[part 13 of 23: package /Cluster]
AUTOSAR XML (schema 4-3-0)
package /Cluster  (continued)
  7 x lin cluster, all with baudrate=19200, protocol-name=LIN, protocol-version=2.0:  (continued)
    Klima_LIN7
      lin physical channel CHNL: comm-connectors=CN_Klima_LIN7
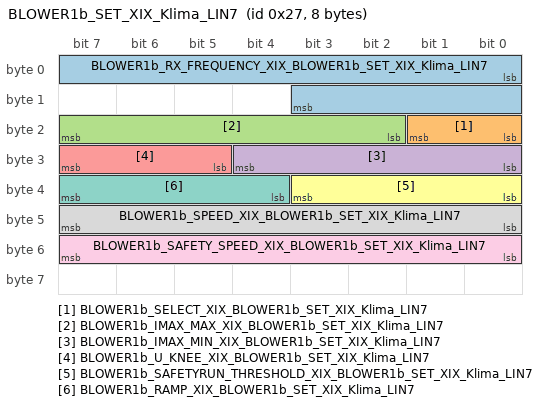
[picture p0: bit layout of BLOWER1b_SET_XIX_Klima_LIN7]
        frame BLOWER1b_SET_XIX_Klima_LIN7: id 0x27, from Klima, frame-length=8, lin-checksum=ENHANCED
          pdu BLOWER1b_SET_XIX_Klima_LIN7: length=8, unused-bit-pattern=0
            signal BLOWER1b_RX_FREQUENCY_XIX_BLOWER1b_SET_XIX_Klima_LIN7: start 0, 12 bit, little-endian, data-type-policy=OVERRIDE, i-signal-type=PRIMITIVE, base-type=BT_BLOWER1b_RX_FREQUENCY, compu {phys=raw+150 for raw 0..1896, 4095=Cxfff_ungueltig (CM_BLOWER1b_RX_FREQUENCY_Cxfff_ungueltig); unit Unit_KiloHertz}, range phys 150..2046 Unit_KiloHertz, raw 0..4095, unit=Unit_KiloHertz, transfer-property=PENDING  # Radio-Empfangsfrequenz bei AM-Empfang 0..1896: Radio RX-Frequenz in kHz 150 kHz.. 2046 kHz (Offset 150 kHz) diese Frequenz Störungsfrei halten. 1897 .. 4094 rerserviert, Ersatzwert: oberste einstellbare Frequenz 4095: ungueltig, Ersatzwert: oberste einstellbare Frequenz
            signal BLOWER1b_SELECT_XIX_BLOWER1b_SET_XIX_Klima_LIN7: start 16, 2 bit, little-endian, data-type-policy=OVERRIDE, i-signal-type=PRIMITIVE, init-value=0, base-type=BT_BLOWER1b_SELECT, compu {0=Cx0_BLOWER1 (CM_BLOWER1b_SELECT_Cx0_BLOWER1), 1=Cx1_BLOWER3 (CM_BLOWER1b_SELECT_Cx1_BLOWER3), 2=Cx2_reserviert (CM_BLOWER1b_SELECT_Cx2_reserviert), 3=Cx3_ungueltig (CM_BLOWER1b_SELECT_Cx3_ungueltig)}, range raw 0..3, transfer-property=PENDING  # 00 : Blower 1 wenn / when ID-field = 0x27 Blower 2 wenn / when ID-field = 0x3A 01 : Blower 3 wenn / when ID-field = 0x27 Blower 4 wenn/ when ID-field = 0x3A 10 : reserviert, Ersatzwert: Blower 2 11 : ungültig, Ersatzwert: Blower 2
            signal BLOWER1b_IMAX_MAX_XIX_BLOWER1b_SET_XIX_Klima_LIN7: start 18, 6 bit, little-endian, data-type-policy=OVERRIDE, i-signal-type=PRIMITIVE, init-value=0, base-type=BT_BLOWER1b_IMAX_MAX, compu {phys=raw*0.5+8 for raw 0..62, 63=Cx3f_ungueltig (CM_BLOWER1b_IMAX_MAX_Cx3f_ungueltig); unit Unit_Amper}, range phys 8..39 Unit_Amper, raw 0..63, unit=Unit_Amper, transfer-property=PENDING  # Vorgabe Maximalstrombegrenzung bei hoher Motorspannung 0.. 62 : Maximalstrom 8 A .. 39 A, Auflösung 0,5 A*inc + 8A. 63 : ungueltig Ersatzwert: niedrigster einstellbarer Wert Regler begrenzt auf Maximalwert
            signal BLOWER1b_IMAX_MIN_XIX_BLOWER1b_SET_XIX_Klima_LIN7: start 24, 5 bit, little-endian, data-type-policy=OVERRIDE, i-signal-type=PRIMITIVE, init-value=0, base-type=BT_BLOWER1b_IMAX_MIN, compu {phys=raw*0.5+2 for raw 0..30, 31=Cx1f_ungueltig (CM_BLOWER1b_IMAX_MIN_Cx1f_ungueltig); unit Unit_Amper}, range phys 2..17 Unit_Amper, raw 0..31, unit=Unit_Amper, transfer-property=PENDING  # Vorgabe Maximalstrombegrenzung bei kleiner Motorspannung (Umotor < 2 V) 0 .. 30 : Maximalstrom 2 A .. 17 A, Aufloesung 0,5 A*inc + 2 A. 31 : Ungueltig Ersatzwert: niedrigster einstellbarer Wert Der Geblaeseregler darf zu hohe oder zu kleine Vorgaben auf die applikationsspezifischen Werte begrenzen.
            signal BLOWER1b_U_KNEE_XIX_BLOWER1b_SET_XIX_Klima_LIN7: start 29, 3 bit, little-endian, data-type-policy=OVERRIDE, i-signal-type=PRIMITIVE, init-value=0, base-type=BT_BLOWER1b_U_KNEE, compu {phys=raw*0.5+8.5 for raw 0..6, 7=Cx7_ungueltig (CM_BLOWER1b_U_KNEE_Cx7_ungueltig); unit Unit_Volt}, range phys 8.5..11.5 Unit_Volt, raw 0..7, unit=Unit_Volt, transfer-property=PENDING  # Vorgabe Knickspannung Strombegrenzung 0 ¿ 6 : Knick bei Umot = 8,5 ¿ 11,5 V, Auflösung 0,5 V * inc + 8,5 V. 7 : Ungültig Ersatzwert 12.0 V Die Knickspannung wird entsprechend dem gesendeten Wert vom Regler eingestellt.
            signal BLOWER1b_SAFETYRUN_THRESHOLD_XIX_BLOWER1b_SET_XIX_Klima_LIN7: start 32, 4 bit, little-endian, data-type-policy=OVERRIDE, i-signal-type=PRIMITIVE, init-value=0, base-type=BT_BLOWER1b_SAFETYRUN_THRESHOLD, compu {phys=raw*0.1+11.5 for raw 0..14, 15=Cxf_ungueltig (CM_BLOWER1b_SAFETYRUN_THRESHOLD_Cxf_ungueltig); unit Unit_Volt}, range phys 11.5..12.9 Unit_Volt, raw 0..15, unit=Unit_Volt, transfer-property=PENDING  # Freigabe Notlauf und Schwellen 0 ... 14 : Schwelle Motor aus bei Ubatt < 11,5 V ¿ 12,9 V Auflösung 0,1 V * inc + 11,5 V 15 : Ungültig Schwelle Motor aus bei Ubatt < 13 V Entsprechend dem gesendeten Wert wird der Notlauf bei Unterschreiten der Batteriespannung abgeschaltet.
            signal BLOWER1b_RAMP_XIX_BLOWER1b_SET_XIX_Klima_LIN7: start 36, 4 bit, little-endian, data-type-policy=OVERRIDE, i-signal-type=PRIMITIVE, init-value=0, base-type=BT_BLOWER1b_RAMP, compu {0=Cx0_LessThan_0_12V_s_Testrampe (CM_BLOWER1b_RAMP_Cx0_LessThan_0_12V_s_Testrampe), phys=raw*0.5 for raw 1..14, 15=Cxf_ungueltig (CM_BLOWER1b_RAMP_Cxf_ungueltig); unit Unit_VoltPerSecon}, range phys 0.5..7 Unit_VoltPerSecon, raw 0..15, unit=Unit_VoltPerSecon, transfer-property=PENDING  # Vorgabe Rampenzeitkonstante DUmotor / s 0 : < 0,12 V / s (Testrampe) 1 .. 14: 0,5 V / sec. bis 7 V / s Auflösung: 0,5 V / s * inc 15 : Ungültig Ersatzwert 7.5 V / s
            signal BLOWER1b_SPEED_XIX_BLOWER1b_SET_XIX_Klima_LIN7: start 40, 8 bit, little-endian, data-type-policy=OVERRIDE, i-signal-type=PRIMITIVE, init-value=0, base-type=BT_BLOWER1b_SPEED, compu {0=Cx0_Motorspannung_0V (CM_BLOWER1b_SPEED_Cx0_Motorspannung_0V), phys=raw*0.05+1.45 for raw 1..251, 252=Cxfc_sofort_Abschalten_0V (CM_BLOWER1b_SPEED_Cxfc_sofort_Abschalten_0V), 253=Cxfd_senken_mit_Rampe_0V (CM_BLOWER1b_SPEED_Cxfd_senken_mit_Rampe_0V), 254=Cxfe_reserviert (CM_BLOWER1b_SPEED_Cxfe_reserviert), 255=Cxff_ungueltig (CM_BLOWER1b_SPEED_Cxff_ungueltig); unit Unit_Volt}, range phys 1.5..14 Unit_Volt, raw 0..255, unit=Unit_Volt, transfer-property=PENDING  # Vorgabe Sollwert Motorspannung 0 : 0 V 1 ... 251: 1,5 V bis 14,0 V Auflösung: 50 mV * inc + 1,45 V 1.5 V to 14.0 V 252 : 0 V sofort Abschalten 253 : 0 V Senken mit Rampe 254 : reserviert 255 : Ungültig Sofort Abschalten Der Gebläseregler darf zu hohe oder zu kleine Vorgaben auf die spezifizierten Werte begrenzen.
            signal BLOWER1b_SAFETY_SPEED_XIX_BLOWER1b_SET_XIX_Klima_LIN7: start 48, 8 bit, little-endian, data-type-policy=OVERRIDE, i-signal-type=PRIMITIVE, init-value=0, base-type=BT_BLOWER1b_SAFETY_SPEED, compu {phys=raw*0.05+1.5 for raw 0..250, 251=Cxfb_reserviert (CM_BLOWER1b_SAFETY_SPEED_Cxfb_reserviert), 252=Cxfc_reserviert (CM_BLOWER1b_SAFETY_SPEED_Cxfc_reserviert), 253=Cxfd_Notlauf_dis_sofort_Abschalten_0V (CM_BLOWER1b_SAFETY_SPEED_Cxfd_Notlauf_dis_sofort_Abschalten_0V), 254=Cxfe_Notlauf_disabled_0V (CM_BLOWER1b_SAFETY_SPEED_Cxfe_Notlauf_disabled_0V), 255=Cxff_ungueltig (CM_BLOWER1b_SAFETY_SPEED_Cxff_ungueltig); unit Unit_Volt}, range phys 1.5..14 Unit_Volt, raw 0..255, unit=Unit_Volt, transfer-property=PENDING  # Vorgabe Sollwert Notlaufmotorspannung 0 ... 252: 1,5 V bis 14,0 V Notlaufmotorspannung Auflösung: 50 mV * inc + 1,5 V 253 : 0 V, Notlauf disabled sofort Abschalten 254 : 0,0 V Notlauf disabled (senken mit Rampe) 255 : Ungültig Sofort Abschalten Der gesendete Wert wird eingestellt. Der Gebläseregler darf zu hohe oder zu kleine Vorgaben auf die spezifizierten Werte begrenzen.
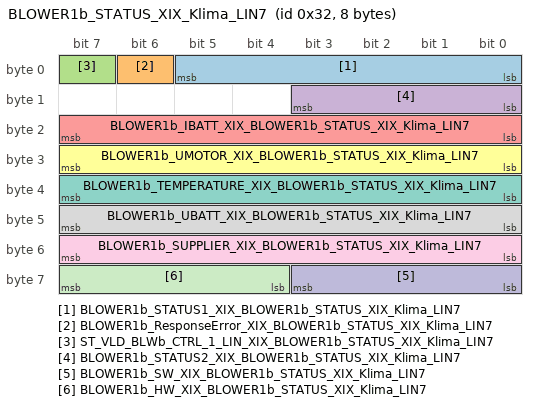
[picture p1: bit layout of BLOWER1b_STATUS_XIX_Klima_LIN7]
        frame BLOWER1b_STATUS_XIX_Klima_LIN7: id 0x32, to Klima, frame-length=8, lin-checksum=ENHANCED
          pdu BLOWER1b_STATUS_XIX_Klima_LIN7: length=8, unused-bit-pattern=0
            signal BLOWER1b_STATUS1_XIX_BLOWER1b_STATUS_XIX_Klima_LIN7: start 0, 6 bit, little-endian, data-type-policy=OVERRIDE, i-signal-type=PRIMITIVE, init-value=0, base-type=BT_BLOWER1b_STATUS1, compu {0=Cx0_Init (CM_BLOWER1b_STATUS1_Cx0_Init), 1=Cx1_int_Fehler_detektiert_Notabsch (CM_BLOWER1b_STATUS1_Cx1_int_Fehler_detektiert_Notabsch), 2=Cx2_Kurzschl_o_blockiert_Motor_aus (CM_BLOWER1b_STATUS1_Cx2_Kurzschl_o_blockiert_Motor_aus), 4=Cx4_Uebertemperaturbegrenzung_aktiv (CM_BLOWER1b_STATUS1_Cx4_Uebertemperaturbegrenzung_aktiv), 8=Cx8_Unterbrechung_zum_Motor_detekt (CM_BLOWER1b_STATUS1_Cx8_Unterbrechung_zum_Motor_detekt), 16=Cx10_Ueberspannung_Abschaltung (CM_BLOWER1b_STATUS1_Cx10_Ueberspannung_Abschaltung), 32=Cx20_Unterspannung_Abschaltung (CM_BLOWER1b_STATUS1_Cx20_Unterspannung_Abschaltung)}, range raw 0..32, transfer-property=PENDING, to Klima(timeout 3.5 s)  # Status Gebläseregler 2^0 : interner Fehler detektiert, Notabschaltung 2^1 : Kurzschluss oder blockiert, Motor aus 2^2 : Übertemperaturbegrenzung aktiv 2^3 : Unterbrechung zum Motor detektiert 2^4 : Überspannung Abschaltung 2^5 : Unterspannung Abschaltung
            signal BLOWER1b_ResponseError_XIX_BLOWER1b_STATUS_XIX_Klima_LIN7: start 6, 1 bit, little-endian, data-type-policy=OVERRIDE, i-signal-type=PRIMITIVE, init-value=0, base-type=BT_BLOWER1b_ResponseError, invalid-value=Invalid_BLOWER1b_ResponseError_XIX_BLOWER1b_STATUS_XIX_Klima_LIN7:1, compu {0=Cx0_normal (CM_BLOWER1b_ResponseError_Cx0_normal), 1=Cx1_Fehler (CM_BLOWER1b_ResponseError_Cx1_Fehler)}, range raw 0..1, transfer-property=PENDING, to Klima(timeout 3.5 s)  # siehe LIN2.0-Specification (Darf nicht über ein Fehlergueltigkeitsbit abgesichtert werden!)
            signal ST_VLD_BLWb_CTRL_1_LIN_XIX_BLOWER1b_STATUS_XIX_Klima_LIN7: start 7, 1 bit, little-endian, data-type-policy=OVERRIDE, i-signal-type=PRIMITIVE, init-value=0, base-type=BT_ST_VLD_BLWb_CTRL_1_LIN, compu {0=Cx0_normal (CM_ST_VLD_BLWb_CTRL_1_LIN_Cx0_normal), 1=Cx1_Blower_Status1_ungueltig_ignor (CM_ST_VLD_BLWb_CTRL_1_LIN_Cx1_Blower_Status1_ungueltig_ignor)}, range raw 0..1, transfer-property=PENDING, to Klima(timeout 3.5 s)  # Status Gebläseregler: 0: normal 1: Blower Status 1 ungültig, ignorieren
            signal BLOWER1b_STATUS2_XIX_BLOWER1b_STATUS_XIX_Klima_LIN7: start 8, 4 bit, little-endian, data-type-policy=OVERRIDE, i-signal-type=PRIMITIVE, init-value=0, base-type=BT_BLOWER1b_STATUS2, compu {0=Cx0_Init (CM_BLOWER1b_STATUS2_Cx0_Init), 1=Cx1_Strombegrenzung_aktiv (CM_BLOWER1b_STATUS2_Cx1_Strombegrenzung_aktiv), 2=Cx2_Sollwert_erreicht (CM_BLOWER1b_STATUS2_Cx2_Sollwert_erreicht), 4=Cx4_Notlauf_aktiviert (CM_BLOWER1b_STATUS2_Cx4_Notlauf_aktiviert), 8=Cx8_Blower_Status_2_ungultig_ignori (CM_BLOWER1b_STATUS2_Cx8_Blower_Status_2_ungultig_ignori)}, range raw 0..8, transfer-property=PENDING, to Klima(timeout 3.5 s)  # Status Gebläseregler 2^0 : Strombegrenzung aktiv 2^1 : Sollwert erreicht 2^2 : Notlauf aktiviert 2^3 : Blower Status 2 ungültig, ignorieren
            signal BLOWER1b_IBATT_XIX_BLOWER1b_STATUS_XIX_Klima_LIN7: start 16, 8 bit, little-endian, data-type-policy=OVERRIDE, i-signal-type=PRIMITIVE, init-value=0, base-type=BT_BLOWER1b_IBATT, compu {phys=raw*0.25 for raw 0..253, 254=Cxfe_kein_Messwert_verfuegbar (CM_BLOWER1b_IBATT_Cxfe_kein_Messwert_verfuegbar), 255=Cxff_Fehler_Strommesseinrichtung (CM_BLOWER1b_IBATT_Cxff_Fehler_Strommesseinrichtung); unit Unit_Amper}, range phys 0..63.25 Unit_Amper, raw 0..255, unit=Unit_Amper, transfer-property=PENDING, to Klima(timeout 3.5 s)  # Stromaufnahme Gebläseregler 0 ... 253: 0 A ... bis 63,25 A, Auflösung: 0,25 A / inc 254 : kein Messwert verfügbar 255 : Fehler Strommesseinrichtung
            signal BLOWER1b_UMOTOR_XIX_BLOWER1b_STATUS_XIX_Klima_LIN7: start 24, 8 bit, little-endian, data-type-policy=OVERRIDE, i-signal-type=PRIMITIVE, init-value=0, base-type=BT_BLOWER1b_UMOTOR, compu {phys=raw*0.1 for raw 0..253, 254=Cxfe_kein_Messwert_verfuegbar (CM_BLOWER1b_UMOTOR_Cxfe_kein_Messwert_verfuegbar), 255=Cxff_Fehler_Spannungsmesseinrichtung (CM_BLOWER1b_UMOTOR_Cxff_Fehler_Spannungsmesseinrichtung); unit Unit_Volt}, range phys 0..25.3 Unit_Volt, raw 0..255, unit=Unit_Volt, transfer-property=PENDING, to Klima(timeout 3.5 s)  # Spannung am Gebläsemotor Umot 0 ... 253 : 0 V ... 25,3 V, Auflösung/Resolution: 0,1 V / inc 254 : kein Messwert verfügbar 255 : Fehler Spannungsmesseinrichtung Der Messbereich des Gebläsereglers darf kleiner 25,3 V sein. Bei Bereichsüberschreitung ist 254 zurückzumelden.
            signal BLOWER1b_TEMPERATURE_XIX_BLOWER1b_STATUS_XIX_Klima_LIN7: start 32, 8 bit, little-endian, data-type-policy=OVERRIDE, i-signal-type=PRIMITIVE, init-value=0, base-type=BT_BLOWER1b_TEMPERATURE, compu {phys=raw-40 for raw 0..190, phys=150 for raw 191..253, 254=Cxfe_kein_Messwert_verfuegbar (CM_BLOWER1b_TEMPERATURE_Cxfe_kein_Messwert_verfuegbar) (kein Messwert verfügbar), 255=Cxff_Fehler_Temperaturmesseinrichtung (CM_BLOWER1b_TEMPERATURE_Cxff_Fehler_Temperaturmesseinrichtung) (Fehler Temperaturmesseinrichtung); unit Unit_DegreCelsi}, range phys -40..150 Unit_DegreCelsi, phys 150 Unit_DegreCelsi, raw 0..255, raw 191..255, unit=Unit_DegreCelsi, transfer-property=PENDING, to Klima(timeout 3.5 s)  # Temperatur Gebläseregler 0 ... 190 : -40 °C ... 150 °C, Auflösung / Resolution: 1 K / inc 191 ... 253 : 150 °C 254 : kein Messwert verfügbar 255 : Fehler Temperaturmesseinrichtung
            signal BLOWER1b_UBATT_XIX_BLOWER1b_STATUS_XIX_Klima_LIN7: start 40, 8 bit, little-endian, data-type-policy=OVERRIDE, i-signal-type=PRIMITIVE, init-value=0, base-type=BT_BLOWER1b_UBATT, compu {phys=raw*0.1 for raw 0..253, 254=Cxfe_kein_Messwert_verfuegbar (CM_BLOWER1b_UBATT_Cxfe_kein_Messwert_verfuegbar), 255=Cxff_Fehler_Spannungsmesseinrichtung (CM_BLOWER1b_UBATT_Cxff_Fehler_Spannungsmesseinrichtung); unit Unit_Volt}, range phys 0..25.3 Unit_Volt, raw 0..255, unit=Unit_Volt, transfer-property=PENDING, to Klima(timeout 3.5 s)  # Spannung am Gebläseregler UBatt 0 ... 253 : 0 V ... 25,3 V, Auflösung / Resolution: 0,1 V / inc 254 : kein Messwert verfügbar 255 : Fehler Spannungsmesseinrichtung
            signal BLOWER1b_SUPPLIER_XIX_BLOWER1b_STATUS_XIX_Klima_LIN7: start 48, 8 bit, little-endian, data-type-policy=OVERRIDE, i-signal-type=PRIMITIVE, init-value=0, base-type=BT_BLOWER1b_SUPPLIER, compu {phys=raw for raw 0..48, 64=Cx40_BOSCH (CM_BLOWER1b_SUPPLIER_Cx40_BOSCH), 102=Cx66_VALEO (CM_BLOWER1b_SUPPLIER_Cx66_VALEO); unit Unit_None}, range phys 0..48 Unit_None, raw 0..102, unit=Unit_None, transfer-property=PENDING, to Klima(timeout 3.5 s)  # Hersteller-Nummer 40h : BOSCH
            signal BLOWER1b_SW_XIX_BLOWER1b_STATUS_XIX_Klima_LIN7: start 56, 4 bit, little-endian, data-type-policy=OVERRIDE, i-signal-type=PRIMITIVE, init-value=0, base-type=BT_BLOWER1b_SW, compu {phys=raw for raw 0..15; unit Unit_None}, range phys 0..15 Unit_None, raw 0..15, unit=Unit_None, transfer-property=PENDING, to Klima(timeout 3.5 s)  # Software-Version 0..F: Version 1¿16
            signal BLOWER1b_HW_XIX_BLOWER1b_STATUS_XIX_Klima_LIN7: start 60, 4 bit, little-endian, data-type-policy=OVERRIDE, i-signal-type=PRIMITIVE, init-value=0, base-type=BT_BLOWER1b_HW, compu {phys=raw for raw 0..15; unit Unit_None}, range phys 0..15 Unit_None, raw 0..15, unit=Unit_None, transfer-property=PENDING, to Klima(timeout 3.5 s)  # Hardware-Version 0..F: Version 1¿16
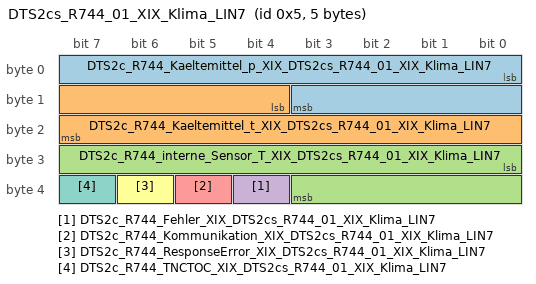
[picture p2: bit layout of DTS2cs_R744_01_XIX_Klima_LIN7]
        frame DTS2cs_R744_01_XIX_Klima_LIN7: id 0x5, to Klima, frame-length=5, lin-checksum=ENHANCED
          pdu DTS2cs_R744_01_XIX_Klima_LIN7: length=5, unused-bit-pattern=0
            signal DTS2c_R744_Kaeltemittel_p_XIX_DTS2cs_R744_01_XIX_Klima_LIN7: start 0, 12 bit, little-endian, data-type-policy=OVERRIDE, i-signal-type=PRIMITIVE, init-value=4094, base-type=BT_DTS2c_R744_Kaeltemittel_p, invalid-value=Invalid_DTS2c_R744_Kaeltemittel_p_XIX_DTS2cs_R744_01_XIX_Klima_LIN7:4095, compu {phys=raw*0.05000000075 for raw 0..3400, 4094=Cxffe_Init (CM_DTS2c_R744_Kaeltemittel_p_Cxffe_Init), 4095=Cxfff_Fehler (CM_DTS2c_R744_Kaeltemittel_p_Cxfff_Fehler); unit Unit_Bar}, range phys 0..170.0000025331974 Unit_Bar, raw 0..4095, unit=Unit_Bar, transfer-property=PENDING, to Klima(timeout 3.5 s)  # Kaeltemitteldruck absolut
            signal DTS2c_R744_Kaeltemittel_t_XIX_DTS2cs_R744_01_XIX_Klima_LIN7: start 12, 12 bit, little-endian, data-type-policy=OVERRIDE, i-signal-type=PRIMITIVE, init-value=4094, base-type=BT_DTS2c_R744_Kaeltemittel_t, invalid-value=Invalid_DTS2c_R744_Kaeltemittel_t_XIX_DTS2cs_R744_01_XIX_Klima_LIN7:4095, compu {phys=raw*0.1000000015-40 for raw 0..2200, 4094=Cxffe_Init (CM_DTS2c_R744_Kaeltemittel_t_Cxffe_Init), 4095=Cxfff_Fehler (CM_DTS2c_R744_Kaeltemittel_t_Cxfff_Fehler); unit Unit_DegreCelsi}, range phys -40..180.00000327825546 Unit_DegreCelsi, raw 0..4095, unit=Unit_DegreCelsi, transfer-property=PENDING, to Klima(timeout 3.5 s)  # Kältemitteltemperatur
            signal DTS2c_R744_interne_Sensor_T_XIX_DTS2cs_R744_01_XIX_Klima_LIN7: start 24, 12 bit, little-endian, data-type-policy=OVERRIDE, i-signal-type=PRIMITIVE, init-value=4094, base-type=BT_DTS2c_R744_interne_Sensor_T, invalid-value=Invalid_DTS2c_R744_interne_Sensor_T_XIX_DTS2cs_R744_01_XIX_Klima_LIN7:4095, compu {phys=raw*0.1000000015-40 for raw 0..1800, 4094=Cxffe_Init (CM_DTS2c_R744_interne_Sensor_T_Cxffe_Init), 4095=Cxfff_Fehler (CM_DTS2c_R744_interne_Sensor_T_Cxfff_Fehler); unit Unit_DegreCelsi}, range phys -40..140.00000268220901 Unit_DegreCelsi, raw 0..4095, unit=Unit_DegreCelsi, transfer-property=PENDING, to Klima(timeout 3.5 s)  # interne Sensor-Temperatur
            signal DTS2c_R744_Fehler_XIX_DTS2cs_R744_01_XIX_Klima_LIN7: start 36, 1 bit, little-endian, data-type-policy=OVERRIDE, i-signal-type=PRIMITIVE, init-value=0, base-type=BT_DTS2c_R744_Fehler, invalid-value=Invalid_DTS2c_R744_Fehler_XIX_DTS2cs_R744_01_XIX_Klima_LIN7:1, compu {0=Cx0_kein_Fehler (CM_DTS2c_R744_Fehler_Cx0_kein_Fehler), 1=Cx1_Fehler (CM_DTS2c_R744_Fehler_Cx1_Fehler)}, range raw 0..1, transfer-property=PENDING, to Klima(timeout 3.5 s)  # Interner Sensorfehler
            signal DTS2c_R744_Kommunikation_XIX_DTS2cs_R744_01_XIX_Klima_LIN7: start 37, 1 bit, little-endian, data-type-policy=OVERRIDE, i-signal-type=PRIMITIVE, init-value=0, base-type=BT_DTS2c_R744_Kommunikation, invalid-value=Invalid_DTS2c_R744_Kommunikation_XIX_DTS2cs_R744_01_XIX_Klima_LIN7:1, compu {0=Cx0_kein_Fehler (CM_DTS2c_R744_Kommunikation_Cx0_kein_Fehler), 1=Cx1_Fehler (CM_DTS2c_R744_Kommunikation_Cx1_Fehler)}, range raw 0..1, transfer-property=PENDING, to Klima(timeout 3.5 s)  # Checksummenfehler
            signal DTS2c_R744_ResponseError_XIX_DTS2cs_R744_01_XIX_Klima_LIN7: start 38, 1 bit, little-endian, data-type-policy=OVERRIDE, i-signal-type=PRIMITIVE, init-value=0, base-type=BT_DTS2c_R744_ResponseError, invalid-value=Invalid_DTS2c_R744_ResponseError_XIX_DTS2cs_R744_01_XIX_Klima_LIN7:1, compu {0=Cx0_normal (CM_DTS2c_R744_ResponseError_Cx0_normal), 1=Cx1_Fehler (CM_DTS2c_R744_ResponseError_Cx1_Fehler)}, range raw 0..1, transfer-property=PENDING, to Klima(timeout 3.5 s)  # siehe LIN2.0-Specification (Darf nicht über ein Fehlergueltigkeitsbit abgesichtert werden!)
            signal DTS2c_R744_TNCTOC_XIX_DTS2cs_R744_01_XIX_Klima_LIN7: start 39, 1 bit, little-endian, data-type-policy=OVERRIDE, i-signal-type=PRIMITIVE, init-value=1, base-type=BT_DTS2c_R744_TNCTOC, compu {0=Cx0_DTC_test_completed_this_operation_cylce (CM_DTS2c_R744_TNCTOC_Cx0_DTC_test_completed_this_operation_cylce), 1=Cx1_DTC_test_not_completed_this_operation_cylce (CM_DTS2c_R744_TNCTOC_Cx1_DTC_test_not_completed_this_operation_cylce)}, range raw 0..1, transfer-property=PENDING, to Klima(timeout 3.5 s)  # testNotCompletedThisOperationCycle (TNCTOC)
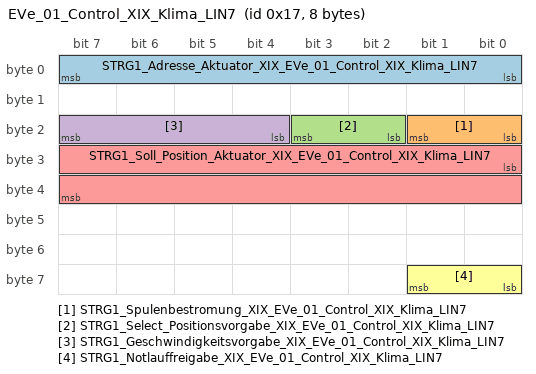
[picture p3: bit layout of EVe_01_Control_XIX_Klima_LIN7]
        frame EVe_01_Control_XIX_Klima_LIN7: id 0x17, from Klima, frame-length=8, lin-checksum=ENHANCED
          pdu EVe_01_Control_XIX_Klima_LIN7: length=8, unused-bit-pattern=0
            signal STRG1_Adresse_Aktuator_XIX_EVe_01_Control_XIX_Klima_LIN7: start 0, 8 bit, little-endian, data-type-policy=OVERRIDE, i-signal-type=PRIMITIVE, base-type=BT_STRG1_Adresse_Aktuator, invalid-value=Invalid_STRG1_Adresse_Aktuator_XIX_EVe_01_Control_XIX_Klima_LIN7:255, compu {phys=raw for raw 0..254, 127=Cx7f_Broadcast (CM_STRG1_Adresse_Aktuator_Cx7f_Broadcast), 255=Cxff_Fehler (CM_STRG1_Adresse_Aktuator_Cxff_Fehler); unit Unit_None}, range phys 0..254 Unit_None, raw 0..255, unit=Unit_None, transfer-property=PENDING  # Zielempfängerauswahl, Steuerungsbotschaft für Aktuatoren
            signal STRG1_Spulenbestromung_XIX_EVe_01_Control_XIX_Klima_LIN7: start 16, 2 bit, little-endian, data-type-policy=OVERRIDE, i-signal-type=PRIMITIVE, base-type=BT_STRG1_Spulenbestromung, invalid-value=Invalid_STRG1_Spulenbestromung_XIX_EVe_01_Control_XIX_Klima_LIN7:3, compu {0=Cx0_Motorspulen_unbestromt (CM_STRG1_Spulenbestromung_Cx0_Motorspulen_unbestromt), 1=Cx1_Motorspulen_bestromt (CM_STRG1_Spulenbestromung_Cx1_Motorspulen_bestromt), 2=Cx2_reserviert (CM_STRG1_Spulenbestromung_Cx2_reserviert), 3=Cx3_Fehler (CM_STRG1_Spulenbestromung_Cx3_Fehler)}, range raw 0..3, transfer-property=PENDING  # Spulenbestromungszustandsvorgabe, Steuerungsbotschaft für Aktuatoren
            signal STRG1_Select_Positionsvorgabe_XIX_EVe_01_Control_XIX_Klima_LIN7: start 18, 2 bit, little-endian, data-type-policy=OVERRIDE, i-signal-type=PRIMITIVE, init-value=2, base-type=BT_STRG1_Select_Positionsvorgabe, invalid-value=Invalid_STRG1_Select_Positionsvorgabe_XIX_EVe_01_Control_XIX_Klima_LIN7:3, compu {0=Cx0_Soll_Position_gueltig (CM_STRG1_Select_Positionsvorgabe_Cx0_Soll_Position_gueltig), 1=Cx1_Start_Position_gueltig (CM_STRG1_Select_Positionsvorgabe_Cx1_Start_Position_gueltig), 2=Cx2_keine_Positionsvorgabe_gueltig (CM_STRG1_Select_Positionsvorgabe_Cx2_keine_Positionsvorgabe_gueltig), 3=Cx3_Fehler (CM_STRG1_Select_Positionsvorgabe_Cx3_Fehler)}, range raw 0..3, transfer-property=PENDING  # Vorgabe der Gültigkeit der Positionsvorgaben, Steuerungsbotschaft für Aktuatoren
            signal STRG1_Geschwindigkeitsvorgabe_XIX_EVe_01_Control_XIX_Klima_LIN7: start 20, 4 bit, little-endian, data-type-policy=OVERRIDE, i-signal-type=PRIMITIVE, base-type=BT_STRG1_Geschwindigkeitsvorgabe, invalid-value=Invalid_STRG1_Geschwindigkeitsvorgabe_XIX_EVe_01_Control_XIX_Klima_LIN7:15, compu {0=Cx0_reserviert (CM_STRG1_Geschwindigkeitsvorgabe_Cx0_reserviert), 1=Cx1_Geschwindigkeitsstufe_1 (CM_STRG1_Geschwindigkeitsvorgabe_Cx1_Geschwindigkeitsstufe_1), 2=Cx2_Geschwindigkeitsstufe_2 (CM_STRG1_Geschwindigkeitsvorgabe_Cx2_Geschwindigkeitsstufe_2), 3=Cx3_Geschwindigkeitsstufe_3 (CM_STRG1_Geschwindigkeitsvorgabe_Cx3_Geschwindigkeitsstufe_3), 4=Cx4_Geschwindigkeitsstufe_4 (CM_STRG1_Geschwindigkeitsvorgabe_Cx4_Geschwindigkeitsstufe_4), 5=Cx5_Autospeed (CM_STRG1_Geschwindigkeitsvorgabe_Cx5_Autospeed), 15=Cxf_Fehler (CM_STRG1_Geschwindigkeitsvorgabe_Cxf_Fehler)}, range raw 0..15, transfer-property=PENDING  # Vorgabe der Geschwindigkeit, Steuerungsbotschaft für Aktuatoren
            signal STRG1_Soll_Position_Aktuator_XIX_EVe_01_Control_XIX_Klima_LIN7: start 24, 16 bit, little-endian, data-type-policy=OVERRIDE, i-signal-type=PRIMITIVE, base-type=BT_STRG1_Soll_Position_Aktuator, invalid-value=Invalid_STRG1_Soll_Position_Aktuator_XIX_EVe_01_Control_XIX_Klima_LIN7:65535, compu {phys=raw for raw 0..65534, 65535=Cxffff_Fehler (CM_STRG1_Soll_Position_Aktuator_Cxffff_Fehler); unit Unit_None}, range phys 0..65534 Unit_None, raw 0..65535, unit=Unit_None, transfer-property=PENDING  # Vorgabe der Sollposition, Steuerungsbotschaft für die Aktuatoren
            signal STRG1_Notlauffreigabe_XIX_EVe_01_Control_XIX_Klima_LIN7: start 56, 2 bit, little-endian, data-type-policy=OVERRIDE, i-signal-type=PRIMITIVE, base-type=BT_STRG1_Notlauffreigabe, invalid-value=Invalid_STRG1_Notlauffreigabe_XIX_EVe_01_Control_XIX_Klima_LIN7:3, compu {0=Cx0_Notlauf_aus (CM_STRG1_Notlauffreigabe_Cx0_Notlauf_aus), 1=Cx1_Notlauf_ein (CM_STRG1_Notlauffreigabe_Cx1_Notlauf_ein), 2=Cx2_reserviert (CM_STRG1_Notlauffreigabe_Cx2_reserviert), 3=Cx3_Fehler (CM_STRG1_Notlauffreigabe_Cx3_Fehler)}, range raw 0..3, transfer-property=PENDING  # Freigabe der Notlaufeigenschaft, Steuerungsbotschaft für Aktuatoren
        frame EXV4s_01_XIX_Klima_LIN7: id 0xE, to Klima, frame-length=8, lin-checksum=ENHANCED
          pdu EXV4s_01_XIX_Klima_LIN7: length=8, unused-bit-pattern=0
            signal EXV4_Ist_Position_Aktuator_XIX_EXV4s_01_XIX_Klima_LIN7: start 0, 16 bit, little-endian, data-type-policy=OVERRIDE, i-signal-type=PRIMITIVE, init-value=65534, base-type=BT_EXV4_Ist_Position_Aktuator, invalid-value=Invalid_EXV4_Ist_Position_Aktuator_XIX_EXV4s_01_XIX_Klima_LIN7:65535, compu {phys=raw for raw 0..65533, 65534=Cxfffe_Init (CM_EXV4_Ist_Position_Aktuator_Cxfffe_Init), 65535=Cxffff_Fehler (CM_EXV4_Ist_Position_Aktuator_Cxffff_Fehler); unit Unit_None}, range phys 0..65533 Unit_None, raw 0..65535, unit=Unit_None, transfer-property=PENDING, to Klima(timeout 3.5 s)  # Statusbotschaft für die elektrischen Kältemittelexpansionsventile
            signal EXV4_Geschwindigkeitsstatus_XIX_EXV4s_01_XIX_Klima_LIN7: start 16, 4 bit, little-endian, data-type-policy=OVERRIDE, i-signal-type=PRIMITIVE, base-type=BT_EXV4_Geschwindigkeitsstatus, invalid-value=Invalid_EXV4_Geschwindigkeitsstatus_XIX_EXV4s_01_XIX_Klima_LIN7:15, compu {0=Cx0_Motor_steht (CM_EXV4_Geschwindigkeitsstatus_Cx0_Motor_steht), 1=Cx1_Geschwindigkeitsstufe_1 (CM_EXV4_Geschwindigkeitsstatus_Cx1_Geschwindigkeitsstufe_1), 2=Cx2_Geschwindigkeitsstufe_2 (CM_EXV4_Geschwindigkeitsstatus_Cx2_Geschwindigkeitsstufe_2), 3=Cx3_Geschwindigkeitsstufe_3 (CM_EXV4_Geschwindigkeitsstatus_Cx3_Geschwindigkeitsstufe_3), 4=Cx4_Geschwindigkeitsstufe_4 (CM_EXV4_Geschwindigkeitsstatus_Cx4_Geschwindigkeitsstufe_4), 5=Cx5_Autospeed (CM_EXV4_Geschwindigkeitsstatus_Cx5_Autospeed), 15=Cxf_Fehler (CM_EXV4_Geschwindigkeitsstatus_Cxf_Fehler)}, range raw 0..15, transfer-property=PENDING, to Klima(timeout 3.5 s)  # Statusbotschaft für die elektrischen Kältemittelexpansionsventile
            signal EXV4_Temp_Warning_XIX_EXV4s_01_XIX_Klima_LIN7: start 20, 1 bit, little-endian, data-type-policy=OVERRIDE, i-signal-type=PRIMITIVE, base-type=BT_EXV4_Temp_Warning, compu {0=Cx0_keine_Warnschwelle (CM_EXV4_Temp_Warning_Cx0_keine_Warnschwelle), 1=Cx1_Warnschwelle_erreicht (CM_EXV4_Temp_Warning_Cx1_Warnschwelle_erreicht)}, range raw 0..1, transfer-property=PENDING, to Klima(timeout 3.5 s)  # Statusbotschaft für die elektrischen Kältemittelexpansionsventile
            signal EXV4_Temp_XIX_EXV4s_01_XIX_Klima_LIN7: start 24, 8 bit, little-endian, data-type-policy=OVERRIDE, i-signal-type=PRIMITIVE, init-value=254, base-type=BT_EXV4_Temp, invalid-value=Invalid_EXV4_Temp_XIX_EXV4s_01_XIX_Klima_LIN7:255, compu {phys=raw-50 for raw 0..253, 254=Cxfe_Init (CM_EXV4_Temp_Cxfe_Init), 255=Cxff_Fehler (CM_EXV4_Temp_Cxff_Fehler); unit Unit_DegreCelsi}, range phys -50..203 Unit_DegreCelsi, raw 0..255, unit=Unit_DegreCelsi, transfer-property=PENDING, to Klima(timeout 3.5 s)  # Platinentemperatur, Statusbotschaft für die elektrischen Kältemittelexpansionsventile
            signal EXV4_Spulenbestromung_XIX_EXV4s_01_XIX_Klima_LIN7: start 32, 2 bit, little-endian, data-type-policy=OVERRIDE, i-signal-type=PRIMITIVE, base-type=BT_EXV4_Spulenbestromung, invalid-value=Invalid_EXV4_Spulenbestromung_XIX_EXV4s_01_XIX_Klima_LIN7:3, compu {0=Cx0_Motorspulen_unbestromt (CM_EXV4_Spulenbestromung_Cx0_Motorspulen_unbestromt), 1=Cx1_Motorspulen_bestromt (CM_EXV4_Spulenbestromung_Cx1_Motorspulen_bestromt), 2=Cx2_reserviert (CM_EXV4_Spulenbestromung_Cx2_reserviert), 3=Cx3_Fehler (CM_EXV4_Spulenbestromung_Cx3_Fehler)}, range raw 0..3, transfer-property=PENDING, to Klima(timeout 3.5 s)  # Statusbotschaft für die elektrischen Kältemittelexpansionsventile
            signal EXV4_ErrMem_State_XIX_EXV4s_01_XIX_Klima_LIN7: start 38, 2 bit, little-endian, data-type-policy=OVERRIDE, i-signal-type=PRIMITIVE, init-value=2, base-type=BT_EXV4_ErrMem_State, compu {0=Cx0_Init_Default (CM_EXV4_ErrMem_State_Cx0_Init_Default), 1=Cx1_ErrMem_Active_State (CM_EXV4_ErrMem_State_Cx1_ErrMem_Active_State), 2=Cx2_ErrMem_InitProgress (CM_EXV4_ErrMem_State_Cx2_ErrMem_InitProgress), 3=Cx3_ErrMem_Init_done (CM_EXV4_ErrMem_State_Cx3_ErrMem_Init_done)}, range raw 0..3, transfer-property=PENDING, to Klima(timeout 3.5 s)  # OBD Signal, Statusbotschaft für die elektrischen Kältemittelexpansionsventile
            signal EXV4_ResponseError_XIX_EXV4s_01_XIX_Klima_LIN7: start 40, 1 bit, little-endian, data-type-policy=OVERRIDE, i-signal-type=PRIMITIVE, init-value=0, base-type=BT_EXV4_ResponseError, invalid-value=Invalid_EXV4_ResponseError_XIX_EXV4s_01_XIX_Klima_LIN7:1, compu {0=Cx0_normal (CM_EXV4_ResponseError_Cx0_normal), 1=Cx1_Fehler (CM_EXV4_ResponseError_Cx1_Fehler)}, range raw 0..1, transfer-property=PENDING, to Klima(timeout 3.5 s)  # siehe LIN2.0-Specification (Darf nicht über ein Fehlergueltigkeitsbit abgesichtert werden!)
            signal EXV4_ResponseError_TNCTOC_XIX_EXV4s_01_XIX_Klima_LIN7: start 41, 1 bit, little-endian, data-type-policy=OVERRIDE, i-signal-type=PRIMITIVE, init-value=1, base-type=BT_EXV4_ResponseError_TNCTOC, compu {0=Cx0_DTC_test_completed_this_operation_cylce (CM_EXV4_ResponseError_TNCTOC_Cx0_DTC_test_completed_this_operation_cylce), 1=Cx1_DTC_test_not_completed_this_operation_cylce (CM_EXV4_ResponseError_TNCTOC_Cx1_DTC_test_not_completed_this_operation_cylce)}, range raw 0..1, transfer-property=PENDING, to Klima(timeout 3.5 s)  # OBD TestFailed Flag, Statusbotschaft für die elektrischen Kältemittelexpansionsventile
            signal EXV4_Err_EDefekt_MoKomp_TF_XIX_EXV4s_01_XIX_Klima_LIN7: start 42, 1 bit, little-endian, data-type-policy=OVERRIDE, i-signal-type=PRIMITIVE, base-type=BT_EXV4_Err_EDefekt_MoKomp_TF, compu {0=Cx0_passive (CM_EXV4_Err_EDefekt_MoKomp_TF_Cx0_passive), 1=Cx1_active (CM_EXV4_Err_EDefekt_MoKomp_TF_Cx1_active)}, range raw 0..1, transfer-property=PENDING, to Klima(timeout 3.5 s)  # OBD TestFailed Flag, Statusbotschaft für die elektrischen Kältemittelexpansionsventile
            signal EXV4_Err_EDefekt_MoKomp_TNCTOC_XIX_EXV4s_01_XIX_Klima_LIN7: start 43, 1 bit, little-endian, data-type-policy=OVERRIDE, i-signal-type=PRIMITIVE, init-value=1, base-type=BT_EXV4_Err_EDefekt_MoKomp_TNCTOC, compu {0=Cx0_DTC_test_completed_this_operation_cylce (CM_EXV4_Err_EDefekt_MoKomp_TNCTOC_Cx0_DTC_test_completed_this_operation_cylce), 1=Cx1_DTC_test_not_completed_this_operation_cylce (CM_EXV4_Err_EDefekt_MoKomp_TNCTOC_Cx1_DTC_test_not_completed_this_operation_cylce)}, range raw 0..1, transfer-property=PENDING, to Klima(timeout 3.5 s)  # OBD TestFailed Flag, Statusbotschaft für die elektrischen Kältemittelexpansionsventile
            signal EXV4_Err_EDefekt_TSens_TF_XIX_EXV4s_01_XIX_Klima_LIN7: start 44, 1 bit, little-endian, data-type-policy=OVERRIDE, i-signal-type=PRIMITIVE, base-type=BT_EXV4_Err_EDefekt_TSens_TF, compu {0=Cx0_passive (CM_EXV4_Err_EDefekt_TSens_TF_Cx0_passive), 1=Cx1_active (CM_EXV4_Err_EDefekt_TSens_TF_Cx1_active)}, range raw 0..1, transfer-property=PENDING, to Klima(timeout 3.5 s)  # OBD TestFailed Flag, Statusbotschaft für die elektrischen Kältemittelexpansionsventile
            signal EXV4_Err_EDefekt_TSens_TNCTOC_XIX_EXV4s_01_XIX_Klima_LIN7: start 45, 1 bit, little-endian, data-type-policy=OVERRIDE, i-signal-type=PRIMITIVE, init-value=1, base-type=BT_EXV4_Err_EDefekt_TSens_TNCTOC, compu {0=Cx0_DTC_test_completed_this_operation_cylce (CM_EXV4_Err_EDefekt_TSens_TNCTOC_Cx0_DTC_test_completed_this_operation_cylce), 1=Cx1_DTC_test_not_completed_this_operation_cylce (CM_EXV4_Err_EDefekt_TSens_TNCTOC_Cx1_DTC_test_not_completed_this_operation_cylce)}, range raw 0..1, transfer-property=PENDING, to Klima(timeout 3.5 s)  # OBD TestFailed Flag, Statusbotschaft für die elektrischen Kältemittelexpansionsventile
            signal EXV4_Err_Uebertemperatur_TF_XIX_EXV4s_01_XIX_Klima_LIN7: start 46, 1 bit, little-endian, data-type-policy=OVERRIDE, i-signal-type=PRIMITIVE, base-type=BT_EXV4_Err_Uebertemperatur_TF, compu {0=Cx0_passive (CM_EXV4_Err_Uebertemperatur_TF_Cx0_passive), 1=Cx1_active (CM_EXV4_Err_Uebertemperatur_TF_Cx1_active)}, range raw 0..1, transfer-property=PENDING, to Klima(timeout 3.5 s)  # OBD TestFailed Flag, Statusbotschaft für die elektrischen Kältemittelexpansionsventile
            signal EXV4_Err_Uebertemperatur_TNCTOC_XIX_EXV4s_01_XIX_Klima_LIN7: start 47, 1 bit, little-endian, data-type-policy=OVERRIDE, i-signal-type=PRIMITIVE, init-value=1, base-type=BT_EXV4_Err_Uebertemperatur_TNCTOC, compu {0=Cx0_DTC_test_completed_this_operation_cylce (CM_EXV4_Err_Uebertemperatur_TNCTOC_Cx0_DTC_test_completed_this_operation_cylce), 1=Cx1_DTC_test_not_completed_this_operation_cylce (CM_EXV4_Err_Uebertemperatur_TNCTOC_Cx1_DTC_test_not_completed_this_operation_cylce)}, range raw 0..1, transfer-property=PENDING, to Klima(timeout 3.5 s)  # OBD TestFailed Flag, Statusbotschaft für die elektrischen Kältemittelexpansionsventile
            signal EXV4_Err_Ueberspannung_TF_XIX_EXV4s_01_XIX_Klima_LIN7: start 48, 1 bit, little-endian, data-type-policy=OVERRIDE, i-signal-type=PRIMITIVE, base-type=BT_EXV4_Err_Ueberspannung_TF, compu {0=Cx0_passive (CM_EXV4_Err_Ueberspannung_TF_Cx0_passive), 1=Cx1_active (CM_EXV4_Err_Ueberspannung_TF_Cx1_active)}, range raw 0..1, transfer-property=PENDING, to Klima(timeout 3.5 s)  # OBD TestFailed Flag, Statusbotschaft für die elektrischen Kältemittelexpansionsventile
            signal EXV4_Err_Ueberspannung_TNCTOC_XIX_EXV4s_01_XIX_Klima_LIN7: start 49, 1 bit, little-endian, data-type-policy=OVERRIDE, i-signal-type=PRIMITIVE, init-value=1, base-type=BT_EXV4_Err_Ueberspannung_TNCTOC, compu {0=Cx0_DTC_test_completed_this_operation_cylce (CM_EXV4_Err_Ueberspannung_TNCTOC_Cx0_DTC_test_completed_this_operation_cylce), 1=Cx1_DTC_test_not_completed_this_operation_cylce (CM_EXV4_Err_Ueberspannung_TNCTOC_Cx1_DTC_test_not_completed_this_operation_cylce)}, range raw 0..1, transfer-property=PENDING, to Klima(timeout 3.5 s)  # OBD TestFailed Flag, Statusbotschaft für die elektrischen Kältemittelexpansionsventile
            signal EXV4_Err_Unterspannung_TF_XIX_EXV4s_01_XIX_Klima_LIN7: start 50, 1 bit, little-endian, data-type-policy=OVERRIDE, i-signal-type=PRIMITIVE, base-type=BT_EXV4_Err_Unterspannung_TF, compu {0=Cx0_passive (CM_EXV4_Err_Unterspannung_TF_Cx0_passive), 1=Cx1_active (CM_EXV4_Err_Unterspannung_TF_Cx1_active)}, range raw 0..1, transfer-property=PENDING, to Klima(timeout 3.5 s)  # OBD TestFailed Flag, Statusbotschaft für die elektrischen Kältemittelexpansionsventile
            signal EXV4_Err_Unterspannung_TNCTOC_XIX_EXV4s_01_XIX_Klima_LIN7: start 51, 1 bit, little-endian, data-type-policy=OVERRIDE, i-signal-type=PRIMITIVE, init-value=1, base-type=BT_EXV4_Err_Unterspannung_TNCTOC, compu {0=Cx0_DTC_test_completed_this_operation_cylce (CM_EXV4_Err_Unterspannung_TNCTOC_Cx0_DTC_test_completed_this_operation_cylce), 1=Cx1_DTC_test_not_completed_this_operation_cylce (CM_EXV4_Err_Unterspannung_TNCTOC_Cx1_DTC_test_not_completed_this_operation_cylce)}, range raw 0..1, transfer-property=PENDING, to Klima(timeout 3.5 s)  # OBD TestFailed Flag, Statusbotschaft für die elektrischen Kältemittelexpansionsventile
            signal EXV4_Err_Blockierung_TF_XIX_EXV4s_01_XIX_Klima_LIN7: start 52, 1 bit, little-endian, data-type-policy=OVERRIDE, i-signal-type=PRIMITIVE, base-type=BT_EXV4_Err_Blockierung_TF, compu {0=Cx0_passive (CM_EXV4_Err_Blockierung_TF_Cx0_passive), 1=Cx1_active (CM_EXV4_Err_Blockierung_TF_Cx1_active)}, range raw 0..1, transfer-property=PENDING, to Klima(timeout 3.5 s)  # OBD TestFailed Flag, Statusbotschaft für die elektrischen Kältemittelexpansionsventile
            signal EXV4_Err_Blockierung_TNCTOC_XIX_EXV4s_01_XIX_Klima_LIN7: start 53, 1 bit, little-endian, data-type-policy=OVERRIDE, i-signal-type=PRIMITIVE, init-value=1, base-type=BT_EXV4_Err_Blockierung_TNCTOC, compu {0=Cx0_DTC_test_completed_this_operation_cylce (CM_EXV4_Err_Blockierung_TNCTOC_Cx0_DTC_test_completed_this_operation_cylce), 1=Cx1_DTC_test_not_completed_this_operation_cylce (CM_EXV4_Err_Blockierung_TNCTOC_Cx1_DTC_test_not_completed_this_operation_cylce)}, range raw 0..1, transfer-property=PENDING, to Klima(timeout 3.5 s)  # OBD TestFailed Flag, Statusbotschaft für die elektrischen Kältemittelexpansionsventile
            signal EXV4_Err_RAMROMNADChange_TF_XIX_EXV4s_01_XIX_Klima_LIN7: start 54, 1 bit, little-endian, data-type-policy=OVERRIDE, i-signal-type=PRIMITIVE, base-type=BT_EXV4_Err_RAMROMNADChange_TF, compu {0=Cx0_passive (CM_EXV4_Err_RAMROMNADChange_TF_Cx0_passive), 1=Cx1_active (CM_EXV4_Err_RAMROMNADChange_TF_Cx1_active)}, range raw 0..1, transfer-property=PENDING, to Klima(timeout 3.5 s)  # OBD TestFailed Flag, Statusbotschaft für die elektrischen Kältemittelexpansionsventile
            signal EXV4_Err_RAMROMNADChange_TNCTOC_XIX_EXV4s_01_XIX_Klima_LIN7: start 55, 1 bit, little-endian, data-type-policy=OVERRIDE, i-signal-type=PRIMITIVE, init-value=1, base-type=BT_EXV4_Err_RAMROMNADChange_TNCTOC, compu {0=Cx0_DTC_test_completed_this_operation_cylce (CM_EXV4_Err_RAMROMNADChange_TNCTOC_Cx0_DTC_test_completed_this_operation_cylce), 1=Cx1_DTC_test_not_completed_this_operation_cylce (CM_EXV4_Err_RAMROMNADChange_TNCTOC_Cx1_DTC_test_not_completed_this_operation_cylce)}, range raw 0..1, transfer-property=PENDING, to Klima(timeout 3.5 s)  # OBD TestFailed Flag, Statusbotschaft für die elektrischen Kältemittelexpansionsventile
            signal EXV4_Err_Notlaufpos_TF_XIX_EXV4s_01_XIX_Klima_LIN7: start 56, 1 bit, little-endian, data-type-policy=OVERRIDE, i-signal-type=PRIMITIVE, base-type=BT_EXV4_Err_Notlaufpos_TF, compu {0=Cx0_passive (CM_EXV4_Err_Notlaufpos_TF_Cx0_passive), 1=Cx1_active (CM_EXV4_Err_Notlaufpos_TF_Cx1_active)}, range raw 0..1, transfer-property=PENDING, to Klima(timeout 3.5 s)  # OBD TestFailed Flag, Statusbotschaft für die elektrischen Kältemittelexpansionsventile
            signal EXV4_Err_Notlaufpos_TNCTOC_XIX_EXV4s_01_XIX_Klima_LIN7: start 57, 1 bit, little-endian, data-type-policy=OVERRIDE, i-signal-type=PRIMITIVE, init-value=1, base-type=BT_EXV4_Err_Notlaufpos_TNCTOC, compu {0=Cx0_DTC_test_completed_this_operation_cylce (CM_EXV4_Err_Notlaufpos_TNCTOC_Cx0_DTC_test_completed_this_operation_cylce), 1=Cx1_DTC_test_not_completed_this_operation_cylce (CM_EXV4_Err_Notlaufpos_TNCTOC_Cx1_DTC_test_not_completed_this_operation_cylce)}, range raw 0..1, transfer-property=PENDING, to Klima(timeout 3.5 s)  # OBD TestFailed Flag, Statusbotschaft für die elektrischen Kältemittelexpansionsventile
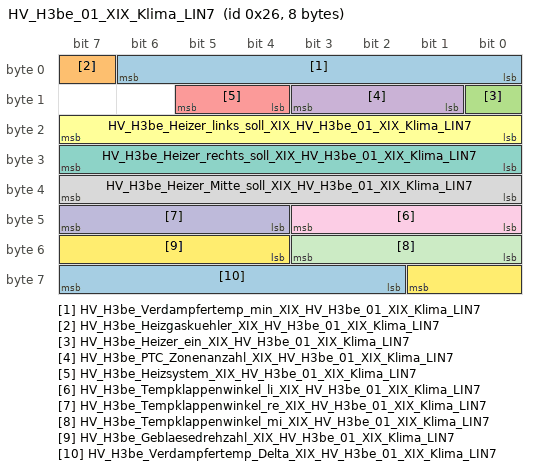
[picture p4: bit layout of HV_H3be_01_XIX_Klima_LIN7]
        frame HV_H3be_01_XIX_Klima_LIN7: id 0x26, from Klima, frame-length=8, lin-checksum=ENHANCED
          pdu HV_H3be_01_XIX_Klima_LIN7: length=8, unused-bit-pattern=0
            signal HV_H3be_Verdampfertemp_min_XIX_HV_H3be_01_XIX_Klima_LIN7: start 0, 7 bit, little-endian, data-type-policy=OVERRIDE, i-signal-type=PRIMITIVE, init-value=126, base-type=BT_HV_H3be_Verdampfertemp_min, invalid-value=Invalid_HV_H3be_Verdampfertemp_min_XIX_HV_H3be_01_XIX_Klima_LIN7:127, compu {phys=raw-30 for raw 0..120, 126=Cx7e_Init (CM_HV_H3be_Verdampfertemp_min_Cx7e_Init), 127=Cx7f_Fehler (CM_HV_H3be_Verdampfertemp_min_Cx7f_Fehler); unit Unit_DegreCelsi}, range phys -30..90 Unit_DegreCelsi, raw 0..127, unit=Unit_DegreCelsi, transfer-property=PENDING  # Minimale Verdampfertemperatur Heizklimagerät
            signal HV_H3be_Heizgaskuehler_XIX_HV_H3be_01_XIX_Klima_LIN7: start 7, 1 bit, little-endian, data-type-policy=OVERRIDE, i-signal-type=PRIMITIVE, init-value=0, base-type=BT_HV_H3be_Heizgaskuehler, compu {0=Cx0_Aus (CM_HV_H3be_Heizgaskuehler_Cx0_Aus), 1=Cx1_Ein (CM_HV_H3be_Heizgaskuehler_Cx1_Ein)}, range raw 0..1, transfer-property=PENDING  # Status Heizgaskühler aus der Wärmepumpe (aus/ein)
            signal HV_H3be_Heizer_ein_XIX_HV_H3be_01_XIX_Klima_LIN7: start 8, 1 bit, little-endian, data-type-policy=OVERRIDE, i-signal-type=PRIMITIVE, init-value=0, base-type=BT_HV_H3be_Heizer_ein, compu {0=Cx0_Aus (CM_HV_H3be_Heizer_ein_Cx0_Aus), 1=Cx1_Ein (CM_HV_H3be_Heizer_ein_Cx1_Ein)}, range raw 0..1, transfer-property=PENDING  # Heizer Aus/Ein
            signal HV_H3be_PTC_Zonenanzahl_XIX_HV_H3be_01_XIX_Klima_LIN7: start 9, 3 bit, little-endian, data-type-policy=OVERRIDE, i-signal-type=PRIMITIVE, init-value=0, base-type=BT_HV_H3be_PTC_Zonenanzahl, compu {0=Cx0_Init (CM_HV_H3be_PTC_Zonenanzahl_Cx0_Init), 1=Cx1_Eine_Zone (CM_HV_H3be_PTC_Zonenanzahl_Cx1_Eine_Zone), 2=Cx2_Zwei_Zonen (CM_HV_H3be_PTC_Zonenanzahl_Cx2_Zwei_Zonen), 3=Cx3_Drei_Zonen (CM_HV_H3be_PTC_Zonenanzahl_Cx3_Drei_Zonen), 4=Cx4_reserviert (CM_HV_H3be_PTC_Zonenanzahl_Cx4_reserviert), 5=Cx5_reserviert (CM_HV_H3be_PTC_Zonenanzahl_Cx5_reserviert), 6=Cx6_reserviert (CM_HV_H3be_PTC_Zonenanzahl_Cx6_reserviert), 7=Cx7_reserviert (CM_HV_H3be_PTC_Zonenanzahl_Cx7_reserviert)}, range raw 0..7, transfer-property=PENDING  # Anzahl Heizzonen
            signal HV_H3be_Heizsystem_XIX_HV_H3be_01_XIX_Klima_LIN7: start 12, 2 bit, little-endian, data-type-policy=OVERRIDE, i-signal-type=PRIMITIVE, base-type=BT_HV_H3be_Heizsystem, compu {0=Cx0_Basis_System (CM_HV_H3be_Heizsystem_Cx0_Basis_System), 1=Cx1_WP (CM_HV_H3be_Heizsystem_Cx1_WP), 2=Cx2_WP_nur_Heizer (CM_HV_H3be_Heizsystem_Cx2_WP_nur_Heizer), 3=Cx3_reserviert (CM_HV_H3be_Heizsystem_Cx3_reserviert)}, range raw 0..3, transfer-property=PENDING  # Info über das verwendete Heizsystem
            signal HV_H3be_Heizer_links_soll_XIX_HV_H3be_01_XIX_Klima_LIN7: start 16, 8 bit, little-endian, data-type-policy=OVERRIDE, i-signal-type=PRIMITIVE, init-value=254, base-type=BT_HV_H3be_Heizer_links_soll, compu {phys=raw for raw 0..100, 254=Cxfe_Init (CM_HV_H3be_Heizer_links_soll_Cxfe_Init); unit Unit_PerCent}, range phys 0..100 Unit_PerCent, raw 0..254, unit=Unit_PerCent, transfer-property=PENDING  # Calculated maximum Heater Power left coming from Master ECU
            signal HV_H3be_Heizer_rechts_soll_XIX_HV_H3be_01_XIX_Klima_LIN7: start 24, 8 bit, little-endian, data-type-policy=OVERRIDE, i-signal-type=PRIMITIVE, init-value=254, base-type=BT_HV_H3be_Heizer_rechts_soll, compu {phys=raw for raw 0..100, 254=Cxfe_Init (CM_HV_H3be_Heizer_rechts_soll_Cxfe_Init); unit Unit_PerCent}, range phys 0..100 Unit_PerCent, raw 0..254, unit=Unit_PerCent, transfer-property=PENDING  # Calculated maximum Heater Power right coming from Master ECU
            signal HV_H3be_Heizer_Mitte_soll_XIX_HV_H3be_01_XIX_Klima_LIN7: start 32, 8 bit, little-endian, data-type-policy=OVERRIDE, i-signal-type=PRIMITIVE, init-value=254, base-type=BT_HV_H3be_Heizer_Mitte_soll, compu {phys=raw for raw 0..100, 254=Cxfe_Init (CM_HV_H3be_Heizer_Mitte_soll_Cxfe_Init); unit Unit_PerCent}, range phys 0..100 Unit_PerCent, raw 0..254, unit=Unit_PerCent, transfer-property=PENDING  # Calculated maximum Heater Power center coming from Master ECU
            signal HV_H3be_Tempklappenwinkel_li_XIX_HV_H3be_01_XIX_Klima_LIN7: start 40, 4 bit, little-endian, data-type-policy=OVERRIDE, i-signal-type=PRIMITIVE, init-value=14, base-type=BT_HV_H3be_Tempklappenwinkel_li, compu {phys=raw*10 for raw 0..10, 14=Cxe_Init (CM_HV_H3be_Tempklappenwinkel_li_Cxe_Init); unit Unit_PerCent}, range phys 0..100 Unit_PerCent, raw 0..14, unit=Unit_PerCent, transfer-property=PENDING  # Temperaturklappenwinkel der Temperaturklappe links
            signal HV_H3be_Tempklappenwinkel_re_XIX_HV_H3be_01_XIX_Klima_LIN7: start 44, 4 bit, little-endian, data-type-policy=OVERRIDE, i-signal-type=PRIMITIVE, init-value=14, base-type=BT_HV_H3be_Tempklappenwinkel_re, compu {phys=raw*10 for raw 0..10, 14=Cxe_Init (CM_HV_H3be_Tempklappenwinkel_re_Cxe_Init); unit Unit_PerCent}, range phys 0..100 Unit_PerCent, raw 0..14, unit=Unit_PerCent, transfer-property=PENDING  # Temperaturklappenwinkel der Temperaturklappe rechts
            signal HV_H3be_Tempklappenwinkel_mi_XIX_HV_H3be_01_XIX_Klima_LIN7: start 48, 4 bit, little-endian, data-type-policy=OVERRIDE, i-signal-type=PRIMITIVE, init-value=14, base-type=BT_HV_H3be_Tempklappenwinkel_mi, compu {phys=raw*10 for raw 0..10, 14=Cxe_Init (CM_HV_H3be_Tempklappenwinkel_mi_Cxe_Init); unit Unit_PerCent}, range phys 0..100 Unit_PerCent, raw 0..14, unit=Unit_PerCent, transfer-property=PENDING  # Temperaturklappenwinkel der Temperaturklappe mitte
            signal HV_H3be_Geblaesedrehzahl_XIX_HV_H3be_01_XIX_Klima_LIN7: start 52, 6 bit, little-endian, data-type-policy=OVERRIDE, i-signal-type=PRIMITIVE, init-value=62, base-type=BT_HV_H3be_Geblaesedrehzahl, invalid-value=Invalid_HV_H3be_Geblaesedrehzahl_XIX_HV_H3be_01_XIX_Klima_LIN7:63, compu {phys=raw*100 for raw 0..50, 62=Cx3e_Init (CM_HV_H3be_Geblaesedrehzahl_Cx3e_Init), 63=Cx3f_Fehler (CM_HV_H3be_Geblaesedrehzahl_Cx3f_Fehler); unit Unit_MinutInver}, range phys 0..5000 Unit_MinutInver, raw 0..63, unit=Unit_MinutInver, transfer-property=PENDING  # Gebläsedrehzahl Frontklimagerät
            signal HV_H3be_Verdampfertemp_Delta_XIX_HV_H3be_01_XIX_Klima_LIN7: start 58, 6 bit, little-endian, data-type-policy=OVERRIDE, i-signal-type=PRIMITIVE, init-value=62, base-type=BT_HV_H3be_Verdampfertemp_Delta, invalid-value=Invalid_HV_H3be_Verdampfertemp_Delta_XIX_HV_H3be_01_XIX_Klima_LIN7:63, compu {phys=raw for raw 0..60, 62=Cx3e_Init (CM_HV_H3be_Verdampfertemp_Delta_Cx3e_Init), 63=Cx3f_Fehler (CM_HV_H3be_Verdampfertemp_Delta_Cx3f_Fehler); unit Unit_DegreCelsi}, range phys 0..60 Unit_DegreCelsi, raw 0..63, unit=Unit_DegreCelsi, transfer-property=PENDING  # Temperaturdelta zu minimal Verdampfertemperatur Heizklimagerät
        frame HV_H3bs_01_XIX_Klima_LIN7: id 0x13, to Klima, frame-length=8, lin-checksum=ENHANCED
          pdu HV_H3bs_01_XIX_Klima_LIN7: length=8, unused-bit-pattern=0
            signal HV_H3b_I_ist_XIX_HV_H3bs_01_XIX_Klima_LIN7: start 0, 8 bit, little-endian, data-type-policy=OVERRIDE, i-signal-type=PRIMITIVE, init-value=254, base-type=BT_HV_H3b_I_ist, invalid-value=Invalid_HV_H3b_I_ist_XIX_HV_H3bs_01_XIX_Klima_LIN7:255, compu {phys=raw*0.25 for raw 0..253, 254=Cxfe_Init (CM_HV_H3b_I_ist_Cxfe_Init), 255=Cxff_Fehler (CM_HV_H3b_I_ist_Cxff_Fehler); unit Unit_Amper}, range phys 0..63.25 Unit_Amper, raw 0..255, unit=Unit_Amper, transfer-property=PENDING, to Klima(timeout 3.5 s)  # HV_H Stromverbrauch (max. 63,25A)
            signal HV_H3b_HIGH_VOLTAGE_XIX_HV_H3bs_01_XIX_Klima_LIN7: start 8, 8 bit, little-endian, data-type-policy=OVERRIDE, i-signal-type=PRIMITIVE, init-value=254, base-type=BT_HV_H3b_HIGH_VOLTAGE, invalid-value=Invalid_HV_H3b_HIGH_VOLTAGE_XIX_HV_H3bs_01_XIX_Klima_LIN7:255, compu {phys=raw*2 for raw 0..253, 254=Cxfe_Init (CM_HV_H3b_HIGH_VOLTAGE_Cxfe_Init), 255=Cxff_Fehler (CM_HV_H3b_HIGH_VOLTAGE_Cxff_Fehler); unit Unit_Volt}, range phys 0..506 Unit_Volt, raw 0..255, unit=Unit_Volt, transfer-property=PENDING, to Klima(timeout 3.5 s)  # Supplied High Voltage
            signal HV_H3b_Status_Heizer_XIX_HV_H3bs_01_XIX_Klima_LIN7: start 16, 3 bit, little-endian, data-type-policy=OVERRIDE, i-signal-type=PRIMITIVE, init-value=7, base-type=BT_HV_H3b_Status_Heizer, compu {0=Cx0_Heizer_OK (CM_HV_H3b_Status_Heizer_Cx0_Heizer_OK), 1=Cx1_Heizer_defekt (CM_HV_H3b_Status_Heizer_Cx1_Heizer_defekt), 2=Cx2_Heizer_error (CM_HV_H3b_Status_Heizer_Cx2_Heizer_error), 3=Cx3_Heizer_degraded_by_HW (CM_HV_H3b_Status_Heizer_Cx3_Heizer_degraded_by_HW), 4=Cx4_Heizer_degraded_by_SW (CM_HV_H3b_Status_Heizer_Cx4_Heizer_degraded_by_SW), 5=Cx5_Heizer_overheat_protection (CM_HV_H3b_Status_Heizer_Cx5_Heizer_overheat_protection), 6=Cx6_not_defined (CM_HV_H3b_Status_Heizer_Cx6_not_defined), 7=Cx7_Init (CM_HV_H3b_Status_Heizer_Cx7_Init)}, range raw 0..7, transfer-property=PENDING, to Klima(timeout 3.5 s)  # Status der HV-Heizer Heizeinheit
            signal HV_H3b_Status_UBatt_NV_XIX_HV_H3bs_01_XIX_Klima_LIN7: start 19, 2 bit, little-endian, data-type-policy=OVERRIDE, i-signal-type=PRIMITIVE, init-value=3, base-type=BT_HV_H3b_Status_UBatt_NV, compu {0=Cx0_Batterie_OK (CM_HV_H3b_Status_UBatt_NV_Cx0_Batterie_OK), 1=Cx1_Unterspannung (CM_HV_H3b_Status_UBatt_NV_Cx1_Unterspannung), 2=Cx2_Ueberspannung (CM_HV_H3b_Status_UBatt_NV_Cx2_Ueberspannung), 3=Cx3_Init (CM_HV_H3b_Status_UBatt_NV_Cx3_Init)}, range raw 0..3, transfer-property=PENDING, to Klima(timeout 3.5 s)  # Status der Batteriespannung
            signal HV_H3b_ResponseError_XIX_HV_H3bs_01_XIX_Klima_LIN7: start 21, 1 bit, little-endian, data-type-policy=OVERRIDE, i-signal-type=PRIMITIVE, init-value=0, base-type=BT_HV_H3b_ResponseError, invalid-value=Invalid_HV_H3b_ResponseError_XIX_HV_H3bs_01_XIX_Klima_LIN7:1, compu {0=Cx0_normal (CM_HV_H3b_ResponseError_Cx0_normal), 1=Cx1_Fehler (CM_HV_H3b_ResponseError_Cx1_Fehler)}, range raw 0..1, transfer-property=PENDING, to Klima(timeout 3.5 s)  # siehe LIN2.0-Specification (Darf nicht über ein Fehlergueltigkeitsbit abgesichtert werden!)
            signal HV_H3b_HIGH_VOLTAGE_ERR_XIX_HV_H3bs_01_XIX_Klima_LIN7: start 22, 2 bit, little-endian, data-type-policy=OVERRIDE, i-signal-type=PRIMITIVE, init-value=0, base-type=BT_HV_H3b_HIGH_VOLTAGE_ERR, compu {0=Cx0_No_Error (CM_HV_H3b_HIGH_VOLTAGE_ERR_Cx0_No_Error), 1=Cx1_High_Voltage_too_low (CM_HV_H3b_HIGH_VOLTAGE_ERR_Cx1_High_Voltage_too_low), 2=Cx2_High_Voltage_too_high (CM_HV_H3b_HIGH_VOLTAGE_ERR_Cx2_High_Voltage_too_high)}, range raw 0..2, transfer-property=PENDING, to Klima(timeout 3.5 s)  # Fehlerstatus HV
            signal HV_H3b_Err_Leckagestrom_XIX_HV_H3bs_01_XIX_Klima_LIN7: start 27, 1 bit, little-endian, data-type-policy=OVERRIDE, i-signal-type=PRIMITIVE, init-value=0, base-type=BT_HV_H3b_Err_Leckagestrom, invalid-value=Invalid_HV_H3b_Err_Leckagestrom_XIX_HV_H3bs_01_XIX_Klima_LIN7:1, compu {0=Cx0_normal (CM_HV_H3b_Err_Leckagestrom_Cx0_normal), 1=Cx1_Fehler (CM_HV_H3b_Err_Leckagestrom_Cx1_Fehler)}, range raw 0..1, transfer-property=PENDING, to Klima(timeout 3.5 s)  # Bit wird gesetzt, wenn Strom fließt obwohl kein Heizkreis angesteuert wird ( IGBT Fehler)
            signal HV_H3b_Err_Ueberstromabschaltung_XIX_HV_H3bs_01_XIX_Klima_LIN7: start 28, 1 bit, little-endian, data-type-policy=OVERRIDE, i-signal-type=PRIMITIVE, init-value=0, base-type=BT_HV_H3b_Err_Ueberstromabschaltung, invalid-value=Invalid_HV_H3b_Err_Ueberstromabschaltung_XIX_HV_H3bs_01_XIX_Klima_LIN7:1, compu {0=Cx0_normal (CM_HV_H3b_Err_Ueberstromabschaltung_Cx0_normal), 1=Cx1_Fehler (CM_HV_H3b_Err_Ueberstromabschaltung_Cx1_Fehler)}, range raw 0..1, transfer-property=PENDING, to Klima(timeout 3.5 s)  # Bit wird gesetzt, wenn über längeren Zeitraum ein zu hoher Gesamtstrom fließt (I Heizkreise > definierte Gesamtstromaufnahme)
            signal HV_H3b_Err_Temperaturschutz_XIX_HV_H3bs_01_XIX_Klima_LIN7: start 29, 1 bit, little-endian, data-type-policy=OVERRIDE, i-signal-type=PRIMITIVE, init-value=0, base-type=BT_HV_H3b_Err_Temperaturschutz, invalid-value=Invalid_HV_H3b_Err_Temperaturschutz_XIX_HV_H3bs_01_XIX_Klima_LIN7:1, compu {0=Cx0_normal (CM_HV_H3b_Err_Temperaturschutz_Cx0_normal), 1=Cx1_Fehler (CM_HV_H3b_Err_Temperaturschutz_Cx1_Fehler)}, range raw 0..1, transfer-property=PENDING, to Klima(timeout 3.5 s)  # Bit wird gesetzt wenn die PlatinenTemperatur ihren Abschaltwert erreicht, Rücknahme bei erreichen der Einschalttemperaturschwelle
            signal HV_H3b_Err_intern_XIX_HV_H3bs_01_XIX_Klima_LIN7: start 30, 1 bit, little-endian, data-type-policy=OVERRIDE, i-signal-type=PRIMITIVE, init-value=0, base-type=BT_HV_H3b_Err_intern, invalid-value=Invalid_HV_H3b_Err_intern_XIX_HV_H3bs_01_XIX_Klima_LIN7:1, compu {0=Cx0_normal (CM_HV_H3b_Err_intern_Cx0_normal), 1=Cx1_Fehler (CM_HV_H3b_Err_intern_Cx1_Fehler)}, range raw 0..1, transfer-property=PENDING, to Klima(timeout 3.5 s)  # Biit soll gesetzt werden, bei allen anderen internen Fehlern, welche denkbar sind (z.B CPU- oder EEPROM Error; AD_Wandler defekt etc)
            signal HV_H3b_TimeOut_Fehler_XIX_HV_H3bs_01_XIX_Klima_LIN7: start 31, 1 bit, little-endian, data-type-policy=OVERRIDE, i-signal-type=PRIMITIVE, init-value=0, base-type=BT_HV_H3b_TimeOut_Fehler, compu {0=Cx0_no_timeout (CM_HV_H3b_TimeOut_Fehler_Cx0_no_timeout), 1=Cx1_timeout_detected (CM_HV_H3b_TimeOut_Fehler_Cx1_timeout_detected)}, range raw 0..1, transfer-property=PENDING, to Klima(timeout 3.5 s)  # Heizer hat zu lange keine Empfangsframes mehr erhalten (Dieser Fehler muss nicht über einen Fehlergueltigkeitsbit abgesichert werden).
            signal HV_H3b_UBatt_NV_XIX_HV_H3bs_01_XIX_Klima_LIN7: start 32, 8 bit, little-endian, data-type-policy=OVERRIDE, i-signal-type=PRIMITIVE, init-value=254, base-type=BT_HV_H3b_UBatt_NV, invalid-value=Invalid_HV_H3b_UBatt_NV_XIX_HV_H3bs_01_XIX_Klima_LIN7:255, compu {phys=raw*0.1 for raw 0..253, 254=Cxfe_Init (CM_HV_H3b_UBatt_NV_Cxfe_Init), 255=Cxff_Fehler (CM_HV_H3b_UBatt_NV_Cxff_Fehler); unit Unit_Volt}, range phys 0..25.3 Unit_Volt, raw 0..255, unit=Unit_Volt, transfer-property=PENDING, to Klima(timeout 3.5 s)  # Gemessene Batteriespannung
            signal HV_H3b_Temp_PCB_XIX_HV_H3bs_01_XIX_Klima_LIN7: start 40, 8 bit, little-endian, data-type-policy=OVERRIDE, i-signal-type=PRIMITIVE, init-value=254, base-type=BT_HV_H3b_Temp_PCB, invalid-value=Invalid_HV_H3b_Temp_PCB_XIX_HV_H3bs_01_XIX_Klima_LIN7:255, compu {phys=raw-50 for raw 0..200, 254=Cxfe_Init (CM_HV_H3b_Temp_PCB_Cxfe_Init), 255=Cxff_Fehler (CM_HV_H3b_Temp_PCB_Cxff_Fehler); unit Unit_DegreCelsi}, range phys -50..150 Unit_DegreCelsi, raw 0..255, unit=Unit_DegreCelsi, transfer-property=PENDING, to Klima(timeout 3.5 s)  # Temperatur der Heizer Ekektronik und der Platine (PCB)
            signal HV_H3b_Status_Heizkreis_1_XIX_HV_H3bs_01_XIX_Klima_LIN7: start 48, 2 bit, little-endian, data-type-policy=OVERRIDE, i-signal-type=PRIMITIVE, init-value=0, base-type=BT_HV_H3b_Status_Heizkreis_1, compu {0=Cx0_normal (CM_HV_H3b_Status_Heizkreis_1_Cx0_normal), 1=Cx1_Degraded_by_Temp (CM_HV_H3b_Status_Heizkreis_1_Cx1_Degraded_by_Temp), 2=Cx2_Switched_off_by_Temp (CM_HV_H3b_Status_Heizkreis_1_Cx2_Switched_off_by_Temp), 3=Cx3_Fehler_HK (CM_HV_H3b_Status_Heizkreis_1_Cx3_Fehler_HK)}, range raw 0..3, transfer-property=PENDING, to Klima(timeout 3.5 s)  # Status vom Heizkreis 1
            signal HV_H3b_Status_Heizkreis_2_XIX_HV_H3bs_01_XIX_Klima_LIN7: start 50, 2 bit, little-endian, data-type-policy=OVERRIDE, i-signal-type=PRIMITIVE, init-value=0, base-type=BT_HV_H3b_Status_Heizkreis_2, compu {0=Cx0_normal (CM_HV_H3b_Status_Heizkreis_2_Cx0_normal), 1=Cx1_Degraded_by_Temp (CM_HV_H3b_Status_Heizkreis_2_Cx1_Degraded_by_Temp), 2=Cx2_Switched_off_by_Temp (CM_HV_H3b_Status_Heizkreis_2_Cx2_Switched_off_by_Temp), 3=Cx3_Fehler_HK (CM_HV_H3b_Status_Heizkreis_2_Cx3_Fehler_HK)}, range raw 0..3, transfer-property=PENDING, to Klima(timeout 3.5 s)  # Status vom Heizkreis 2
            signal HV_H3b_Status_Heizkreis_3_XIX_HV_H3bs_01_XIX_Klima_LIN7: start 52, 2 bit, little-endian, data-type-policy=OVERRIDE, i-signal-type=PRIMITIVE, init-value=0, base-type=BT_HV_H3b_Status_Heizkreis_3, compu {0=Cx0_normal (CM_HV_H3b_Status_Heizkreis_3_Cx0_normal), 1=Cx1_Degraded_by_Temp (CM_HV_H3b_Status_Heizkreis_3_Cx1_Degraded_by_Temp), 2=Cx2_Switched_off_by_Temp (CM_HV_H3b_Status_Heizkreis_3_Cx2_Switched_off_by_Temp), 3=Cx3_Fehler_HK (CM_HV_H3b_Status_Heizkreis_3_Cx3_Fehler_HK)}, range raw 0..3, transfer-property=PENDING, to Klima(timeout 3.5 s)  # Status vom Heizkreis 3
            signal HV_H3b_Status_Heizkreis_4_XIX_HV_H3bs_01_XIX_Klima_LIN7: start 54, 2 bit, little-endian, data-type-policy=OVERRIDE, i-signal-type=PRIMITIVE, init-value=0, base-type=BT_HV_H3b_Status_Heizkreis_4, compu {0=Cx0_normal (CM_HV_H3b_Status_Heizkreis_4_Cx0_normal), 1=Cx1_Degraded_by_Temp (CM_HV_H3b_Status_Heizkreis_4_Cx1_Degraded_by_Temp), 2=Cx2_Switched_off_by_Temp (CM_HV_H3b_Status_Heizkreis_4_Cx2_Switched_off_by_Temp), 3=Cx3_Error_HK (CM_HV_H3b_Status_Heizkreis_4_Cx3_Error_HK)}, range raw 0..3, transfer-property=PENDING, to Klima(timeout 3.5 s)  # Status vom Heizkreis 4
        frame KLhe_01_XIX_Klima_LIN7: id 0x1, from Klima, frame-length=8, lin-checksum=ENHANCED
          pdu KLhe_01_XIX_Klima_LIN7: length=8, unused-bit-pattern=0
            signal KL_Anz_oben_hl_XIX_KLhe_01_XIX_Klima_LIN7: start 0, 1 bit, little-endian, data-type-policy=OVERRIDE, i-signal-type=PRIMITIVE, init-value=0, base-type=BT_KL_Anz_oben_hl, compu {0=Cx0_Aus (CM_KL_Anz_oben_hl_Cx0_Aus), 1=Cx1_Ein (CM_KL_Anz_oben_hl_Cx1_Ein)}, range raw 0..1, transfer-property=PENDING  # VW428
            signal KL_Anz_mitte_hl_XIX_KLhe_01_XIX_Klima_LIN7: start 1, 1 bit, little-endian, data-type-policy=OVERRIDE, i-signal-type=PRIMITIVE, init-value=0, base-type=BT_KL_Anz_mitte_hl, compu {0=Cx0_Aus (CM_KL_Anz_mitte_hl_Cx0_Aus), 1=Cx1_Ein (CM_KL_Anz_mitte_hl_Cx1_Ein)}, range raw 0..1, transfer-property=PENDING  # Rückmeldung "Luftverteilung Mannanströmer Heck"
            signal KL_Anz_unten_hl_XIX_KLhe_01_XIX_Klima_LIN7: start 2, 1 bit, little-endian, data-type-policy=OVERRIDE, i-signal-type=PRIMITIVE, init-value=0, base-type=BT_KL_Anz_unten_hl, compu {0=Cx0_Aus (CM_KL_Anz_unten_hl_Cx0_Aus), 1=Cx1_Ein (CM_KL_Anz_unten_hl_Cx1_Ein)}, range raw 0..1, transfer-property=PENDING  # Rückmeldung "Luftverteilung Fußraum Heck"
            signal KL_Anz_auto_hl_XIX_KLhe_01_XIX_Klima_LIN7: start 3, 1 bit, little-endian, data-type-policy=OVERRIDE, i-signal-type=PRIMITIVE, init-value=0, base-type=BT_KL_Anz_auto_hl, compu {0=Cx0_Aus (CM_KL_Anz_auto_hl_Cx0_Aus), 1=Cx1_Ein (CM_KL_Anz_auto_hl_Cx1_Ein)}, range raw 0..1, transfer-property=PENDING  # Rückmeldung "Auto Heck"
            signal KL_Anz_seite_hl_XIX_KLhe_01_XIX_Klima_LIN7: start 4, 1 bit, little-endian, data-type-policy=OVERRIDE, i-signal-type=PRIMITIVE, init-value=0, base-type=BT_KL_Anz_seite_hl, compu {0=Cx0_Aus (CM_KL_Anz_seite_hl_Cx0_Aus), 1=Cx1_Ein (CM_KL_Anz_seite_hl_Cx1_Ein)}, range raw 0..1, transfer-property=PENDING  # Rückmeldung "Luftverteilung Seitenscheibe Heck"
            signal KL_Anz_seite_defog_hl_XIX_KLhe_01_XIX_Klima_LIN7: start 5, 1 bit, little-endian, data-type-policy=OVERRIDE, i-signal-type=PRIMITIVE, init-value=0, base-type=BT_KL_Anz_seite_defog_hl, compu {0=Cx0_Aus (CM_KL_Anz_seite_defog_hl_Cx0_Aus), 1=Cx1_Ein (CM_KL_Anz_seite_defog_hl_Cx1_Ein)}, range raw 0..1, transfer-property=PENDING  # Rückmeldung "Seitenscheiben-Defog Heck"
            signal KL_KLh_aus_XIX_KLhe_01_XIX_Klima_LIN7: start 8, 1 bit, little-endian, data-type-policy=OVERRIDE, i-signal-type=PRIMITIVE, base-type=BT_KL_KLh_aus, compu {0=Cx0_HeckBT_EIN (CM_KL_KLh_aus_Cx0_HeckBT_EIN), 1=Cx1_HeckBT_AUS (CM_KL_KLh_aus_Cx1_HeckBT_AUS)}, range raw 0..1, transfer-property=PENDING  # Anforderung Heckbedienteil Aus
            signal KL_KLh_LastMode_XIX_KLhe_01_XIX_Klima_LIN7: start 9, 2 bit, little-endian, data-type-policy=OVERRIDE, i-signal-type=PRIMITIVE, base-type=BT_KL_KLh_LastMode, compu {0=Cx0_LastMode_nicht_speichern (CM_KL_KLh_LastMode_Cx0_LastMode_nicht_speichern) (LastMode nicht speichern), 1=Cx1_Speichern_zeitbegrenzt (CM_KL_KLh_LastMode_Cx1_Speichern_zeitbegrenzt) (Speichern (zeitbegrenzt)), 2=Cx2_Speichern (CM_KL_KLh_LastMode_Cx2_Speichern)}, range raw 0..2, transfer-property=PENDING  # Übermittlung an Sitzheizung Heck, ob LastMode zu speichern ist.
            signal KL_KLh_lock_XIX_KLhe_01_XIX_Klima_LIN7: start 11, 1 bit, little-endian, data-type-policy=OVERRIDE, i-signal-type=PRIMITIVE, base-type=BT_KL_KLh_lock, compu {0=Cx0_Bedienung_HeckBT_nicht_gesperrt (CM_KL_KLh_lock_Cx0_Bedienung_HeckBT_nicht_gesperrt) (Bedienung HeckBT nicht gesperrt), 1=Cx1_Bedienung_HeckBT_gesperrt (CM_KL_KLh_lock_Cx1_Bedienung_HeckBT_gesperrt) (Bedienung HeckBT gesperrt)}, range raw 0..1, transfer-property=PENDING  # Das KlimaBT (front) unterbindet die Bedienung der Klimafunktionen des HeckBT durch Fahrgast hintere Reihe.
            signal KL_StellgliedtestINV_Heck_XIX_KLhe_01_XIX_Klima_LIN7: start 12, 1 bit, little-endian, data-type-policy=OVERRIDE, i-signal-type=PRIMITIVE, init-value=1, base-type=BT_KL_StellgliedtestINV_Heck, compu {0=Cx0_aktiv (CM_KL_StellgliedtestINV_Heck_Cx0_aktiv), 1=Cx1_inaktiv (CM_KL_StellgliedtestINV_Heck_Cx1_inaktiv)}, range raw 0..1, transfer-property=PENDING  # KlimaBT sendet an HeckBT Info über Status Stellgliedtest bzgl. Komponenten Heck.
            signal KL_Sitzkennlinie_Heck_XIX_KLhe_01_XIX_Klima_LIN7: start 13, 3 bit, little-endian, data-type-policy=OVERRIDE, i-signal-type=PRIMITIVE, base-type=BT_KL_Sitzkennlinie_Heck, compu {phys=raw for raw 0..7; unit Unit_None}, range phys 0..7 Unit_None, raw 0..7, unit=Unit_None, transfer-property=PENDING  # Globaler fester Satz von Applikationskennlinien Sitzheizung in HeckBT, ausgewählt für Fahrzeugprojekt.
            signal KL_Anz_Temp_hl_XIX_KLhe_01_XIX_Klima_LIN7: start 16, 8 bit, little-endian, data-type-policy=OVERRIDE, i-signal-type=PRIMITIVE, init-value=254, base-type=BT_KL_Anz_Temp_hl, invalid-value=Invalid_KL_Anz_Temp_hl_XIX_KLhe_01_XIX_Klima_LIN7:255, compu {0=Cx0_Low (CM_KL_Anz_Temp_hl_Cx0_Low), phys=raw for raw 1..250, 251=Cxfb_Anzeige_ECO (CM_KL_Anz_Temp_hl_Cxfb_Anzeige_ECO), 252=Cxfc_High (CM_KL_Anz_Temp_hl_Cxfc_High), 253=Cxfd_Keine_TemperaturAnzeige (CM_KL_Anz_Temp_hl_Cxfd_Keine_TemperaturAnzeige), 254=Cxfe_Init (CM_KL_Anz_Temp_hl_Cxfe_Init), 255=Cxff_Fehler (CM_KL_Anz_Temp_hl_Cxff_Fehler); unit Unit_None}, range phys 1..250 Unit_None, raw 0..255, unit=Unit_None, transfer-property=PENDING  # Soll-Temperatur Heck. Interpretation Intervall [1, 250] ist abhängig von Signal "KL_Anz_Temp_Einheit": °C: Offset=-50, Step=0,5 F: Offset=-50, Step=1 TempStufen: Offset=0, Step=1 physikalischer Wertebereich auf [1, 250] begrenzt logischer Wert für "ECO" hinzugefügt
            signal KL_Anz_Geblaese_hl_XIX_KLhe_01_XIX_Klima_LIN7: start 24, 4 bit, little-endian, data-type-policy=OVERRIDE, i-signal-type=PRIMITIVE, init-value=14, base-type=BT_KL_Anz_Geblaese_hl, invalid-value=Invalid_KL_Anz_Geblaese_hl_XIX_KLhe_01_XIX_Klima_LIN7:15, compu {phys=raw for raw 0..12, 13=Cxd_Keine_GeblaeseAnzeige (CM_KL_Anz_Geblaese_hl_Cxd_Keine_GeblaeseAnzeige), 14=Cxe_Init (CM_KL_Anz_Geblaese_hl_Cxe_Init), 15=Cxf_Fehler (CM_KL_Anz_Geblaese_hl_Cxf_Fehler); unit Unit_None}, range phys 0..12 Unit_None, raw 0..15, unit=Unit_None, transfer-property=PENDING  # Gebläsebalken Heck
            signal KL_SIH_Anforderung_hl_XIX_KLhe_01_XIX_Klima_LIN7: start 32, 3 bit, little-endian, data-type-policy=OVERRIDE, i-signal-type=PRIMITIVE, base-type=BT_KL_SIH_Anforderung_hl, compu {0=Cx0_Stufe_0_angefordert (CM_KL_SIH_Anforderung_hl_Cx0_Stufe_0_angefordert) (Stufe_0 angefordert), 1=Cx1_Stufe_1_angefordert (CM_KL_SIH_Anforderung_hl_Cx1_Stufe_1_angefordert) (Stufe_1 angefordert), 2=Cx2_Stufe_2_angefordert (CM_KL_SIH_Anforderung_hl_Cx2_Stufe_2_angefordert) (Stufe_2 angefordert), 3=Cx3_Stufe_3_angefordert (CM_KL_SIH_Anforderung_hl_Cx3_Stufe_3_angefordert) (Stufe_3 angefordert), 4=Cx4_Stufe_4_angefordert (CM_KL_SIH_Anforderung_hl_Cx4_Stufe_4_angefordert) (Stufe_4 angefordert), 5=Cx5_Stufe_5_angefordert (CM_KL_SIH_Anforderung_hl_Cx5_Stufe_5_angefordert) (Stufe_5 angefordert), 6=Cx6_Stufe_6_angefordert (CM_KL_SIH_Anforderung_hl_Cx6_Stufe_6_angefordert) (Stufe_6 angefordert), 7=Cx7_Keine_Anforderung (CM_KL_SIH_Anforderung_hl_Cx7_Keine_Anforderung) (Keine Anforderung)}, range raw 0..7, transfer-property=PENDING  # Anforderung der Sitzheizung Heck linke Seite durch KlimaBT.
            signal KL_SIH_Anforderung_hr_XIX_KLhe_01_XIX_Klima_LIN7: start 35, 3 bit, little-endian, data-type-policy=OVERRIDE, i-signal-type=PRIMITIVE, base-type=BT_KL_SIH_Anforderung_hr, compu {0=Cx0_Stufe_0_angefordert (CM_KL_SIH_Anforderung_hr_Cx0_Stufe_0_angefordert) (Stufe_0 angefordert), 1=Cx1_Stufe_1_angefordert (CM_KL_SIH_Anforderung_hr_Cx1_Stufe_1_angefordert) (Stufe_1 angefordert), 2=Cx2_Stufe_2_angefordert (CM_KL_SIH_Anforderung_hr_Cx2_Stufe_2_angefordert) (Stufe_2 angefordert), 3=Cx3_Stufe_3_angefordert (CM_KL_SIH_Anforderung_hr_Cx3_Stufe_3_angefordert) (Stufe_3 angefordert), 4=Cx4_Stufe_4_angefordert (CM_KL_SIH_Anforderung_hr_Cx4_Stufe_4_angefordert) (Stufe_4 angefordert), 5=Cx5_Stufe_5_angefordert (CM_KL_SIH_Anforderung_hr_Cx5_Stufe_5_angefordert) (Stufe_5 angefordert), 6=Cx6_Stufe_6_angefordert (CM_KL_SIH_Anforderung_hr_Cx6_Stufe_6_angefordert) (Stufe_6 angefordert), 7=Cx7_Keine_Anforderung (CM_KL_SIH_Anforderung_hr_Cx7_Keine_Anforderung) (Keine Anforderung)}, range raw 0..7, transfer-property=PENDING  # Anforderung der Sitzheizung Heck rechte Seite durch KlimaBT.
            signal KL_Anz_Temp_Einheit_XIX_KLhe_01_XIX_Klima_LIN7: start 38, 2 bit, little-endian, data-type-policy=OVERRIDE, i-signal-type=PRIMITIVE, base-type=BT_KL_Anz_Temp_Einheit, compu {0=Cx0_Celsius (CM_KL_Anz_Temp_Einheit_Cx0_Celsius), 1=Cx1_Fahrenheit (CM_KL_Anz_Temp_Einheit_Cx1_Fahrenheit), 2=Cx2_TemperaturStufen (CM_KL_Anz_Temp_Einheit_Cx2_TemperaturStufen), 3=Cx3_reserviert (CM_KL_Anz_Temp_Einheit_Cx3_reserviert)}, range raw 0..3, transfer-property=PENDING  # Vorgabe zur Interpretation der Temperaturanzeuge Heck.
            signal KL_Anz_Temp_hr_XIX_KLhe_01_XIX_Klima_LIN7: start 40, 8 bit, little-endian, data-type-policy=OVERRIDE, i-signal-type=PRIMITIVE, init-value=254, base-type=BT_KL_Anz_Temp_hr, invalid-value=Invalid_KL_Anz_Temp_hr_XIX_KLhe_01_XIX_Klima_LIN7:255, compu {0=Cx0_Low (CM_KL_Anz_Temp_hr_Cx0_Low), phys=raw for raw 1..250, 251=Cxfb_Anzeige_ECO (CM_KL_Anz_Temp_hr_Cxfb_Anzeige_ECO), 252=Cxfc_High (CM_KL_Anz_Temp_hr_Cxfc_High), 253=Cxfd_Keine_TemperaturAnzeige (CM_KL_Anz_Temp_hr_Cxfd_Keine_TemperaturAnzeige), 254=Cxfe_Init (CM_KL_Anz_Temp_hr_Cxfe_Init), 255=Cxff_Fehler (CM_KL_Anz_Temp_hr_Cxff_Fehler); unit Unit_None}, range phys 1..250 Unit_None, raw 0..255, unit=Unit_None, transfer-property=PENDING  # Soll-Temperatur Heck (rechts). Interpretation Intervall [1, 250] ist abhängig von Signal "KL_Anz_Temp_Einheit": °C: Offset=-50, Step=0,5 F: Offset=-50, Step=1 TempStufen: Offset=0, Step=1 physikalischer Wertebereich auf [1, 250] begrenzt logischer Wert für "ECO" hinzugefügt
            signal KL_HBT_Geblaesestufe_anzeigen_XIX_KLhe_01_XIX_Klima_LIN7: start 48, 2 bit, little-endian, data-type-policy=OVERRIDE, i-signal-type=PRIMITIVE, init-value=1, base-type=BT_KL_HBT_Geblaesestufe_anzeigen, compu {0=Cx0_Geblaesestufe_anzeigen (CM_KL_HBT_Geblaesestufe_anzeigen_Cx0_Geblaesestufe_anzeigen), 1=Cx1_Geblaesestufe_ausblenden (CM_KL_HBT_Geblaesestufe_anzeigen_Cx1_Geblaesestufe_ausblenden), 2=Cx2_reserviert (CM_KL_HBT_Geblaesestufe_anzeigen_Cx2_reserviert), 3=Cx3_reserviert (CM_KL_HBT_Geblaesestufe_anzeigen_Cx3_reserviert)}, range raw 0..3, transfer-property=PENDING  # Wenn zwei Heckbedienteile (HBT) im Fahrzeug verbaut sind, wird über dieses Signal eine synchrone Anzeige der Gebläsestufe sichergestellt. Wird an einem HBT die Gebläsestufe verändert, wird über diesen Flag dem anderen HBT signalisiert, die aktuelle Gebläsestufe ebenfalls anzuzeigen.
            signal KL_HBT_Verbausituation_XIX_KLhe_01_XIX_Klima_LIN7: start 50, 2 bit, little-endian, data-type-policy=OVERRIDE, i-signal-type=PRIMITIVE, init-value=1, base-type=BT_KL_HBT_Verbausituation, compu {0=Cx0_Zwei_Heckbedienteile (CM_KL_HBT_Verbausituation_Cx0_Zwei_Heckbedienteile), 1=Cx1_Ein_Heckbedienteil (CM_KL_HBT_Verbausituation_Cx1_Ein_Heckbedienteil), 2=Cx2_reserviert (CM_KL_HBT_Verbausituation_Cx2_reserviert), 3=Cx3_reserviert (CM_KL_HBT_Verbausituation_Cx3_reserviert)}, range raw 0..3, transfer-property=PENDING  # Gibt die Verbausituation der Heckbedienteile (HBT) an. Im Fahrzeug können für die Bedienung der hinteren Klimazone auch mehrere HBTs verbaut sein. Für eine synchrone Anzeige der Geläbsestufe wird über dieses Signal die Verbausituation dauerhaft gesendet.
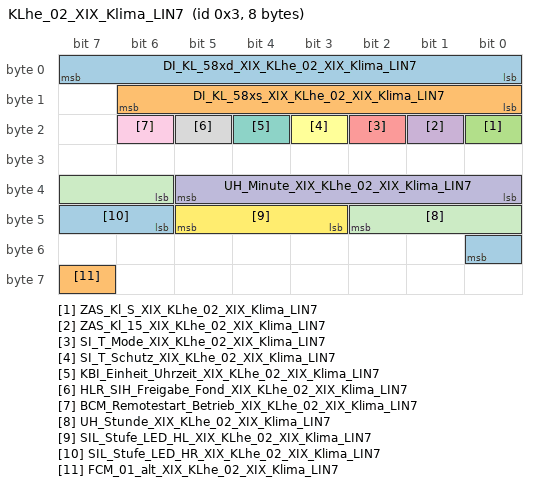
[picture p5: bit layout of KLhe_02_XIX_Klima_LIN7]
        frame KLhe_02_XIX_Klima_LIN7: id 0x3, from Klima, frame-length=8, lin-checksum=ENHANCED
          pdu KLhe_02_XIX_Klima_LIN7: length=8, unused-bit-pattern=0
            signal DI_KL_58xd_XIX_KLhe_02_XIX_Klima_LIN7: start 0, 8 bit, little-endian, data-type-policy=OVERRIDE, i-signal-type=PRIMITIVE, init-value=254, base-type=BT_DI_KL_58xd, invalid-value=Invalid_DI_KL_58xd_XIX_KLhe_02_XIX_Klima_LIN7:255, compu {phys=raw for raw 0..253, 254=Cxfe_Init (CM_DI_KL_58xd_Cxfe_Init), 255=Cxff_Fehler (CM_DI_KL_58xd_Cxff_Fehler)}, range phys 0..253, raw 0..255, transfer-property=PENDING  # Klemme 58xd Display- und Funktionsbeleuchtung Mit der Klemme 58xd wird die Helligkeit der Display- und der Funktionsbeleuchtungen der Schalter gesteuert. Im Detail beschrieben im 'Funktionslastenheft Dimmung MQB'.
            signal DI_KL_58xs_XIX_KLhe_02_XIX_Klima_LIN7: start 8, 7 bit, little-endian, data-type-policy=OVERRIDE, i-signal-type=PRIMITIVE, init-value=126, base-type=BT_DI_KL_58xs, invalid-value=Invalid_DI_KL_58xs_XIX_KLhe_02_XIX_Klima_LIN7:127, compu {phys=raw for raw 0..100, 126=Cx7e_Init (CM_DI_KL_58xs_Cx7e_Init), 127=Cx7f_Fehler (CM_DI_KL_58xs_Cx7f_Fehler); unit Unit_PerCent}, range phys 0..100 Unit_PerCent, raw 0..127, unit=Unit_PerCent, transfer-property=PENDING  # Suchbeleuchtung Schalter EIN-AUS-Schaltalgorithmus der allgemeinen Schaltersuchbeleuchtung. Im Detail beschrieben im 'Funktionslastenheft Dimmung MQB'.
            signal ZAS_Kl_S_XIX_KLhe_02_XIX_Klima_LIN7: start 16, 1 bit, little-endian, data-type-policy=OVERRIDE, i-signal-type=PRIMITIVE, init-value=0, base-type=BT_ZAS_Kl_S, compu {0=Cx0_aus (CM_ZAS_Kl_S_Cx0_aus), 1=Cx1_S_Kontakt_ein (CM_ZAS_Kl_S_Cx1_S_Kontakt_ein)}, range raw 0..1, transfer-property=PENDING  # Klemme S: S-Kontakt (Schluessel steckt)
            signal ZAS_Kl_15_XIX_KLhe_02_XIX_Klima_LIN7: start 17, 1 bit, little-endian, data-type-policy=OVERRIDE, i-signal-type=PRIMITIVE, init-value=0, base-type=BT_ZAS_Kl_15, compu {0=Cx0_aus (CM_ZAS_Kl_15_Cx0_aus), 1=Cx1_ein (CM_ZAS_Kl_15_Cx1_ein)}, range raw 0..1, transfer-property=PENDING  # Klemme 15: Zuendung (SW-Kl.15)
            signal SI_T_Mode_XIX_KLhe_02_XIX_Klima_LIN7: start 18, 1 bit, little-endian, data-type-policy=OVERRIDE, i-signal-type=PRIMITIVE, init-value=0, base-type=BT_SI_T_Mode, compu {0=Cx0_Transportmodus_nicht_aktiv (CM_SI_T_Mode_Cx0_Transportmodus_nicht_aktiv), 1=Cx1_Transportmodus_aktiv (CM_SI_T_Mode_Cx1_Transportmodus_aktiv)}, range raw 0..1, transfer-property=PENDING  # 0x0: Transportmodus nicht aktiv 0x1: Transportmodus aktiv
            signal SI_T_Schutz_XIX_KLhe_02_XIX_Klima_LIN7: start 19, 1 bit, little-endian, data-type-policy=OVERRIDE, i-signal-type=PRIMITIVE, init-value=0, base-type=BT_SI_T_Schutz, compu {0=Cx0_Transportschutz_nicht_aktiv (CM_SI_T_Schutz_Cx0_Transportschutz_nicht_aktiv), 1=Cx1_Transportschutz_aktiv (CM_SI_T_Schutz_Cx1_Transportschutz_aktiv)}, range raw 0..1, transfer-property=PENDING  # Transportschutz-Signal, das bei Transportmodus und Motorlauf aktiv bleibt 0x0: Transportschutz nicht aktiv 0x1: Transportschutz aktiv
            signal KBI_Einheit_Uhrzeit_XIX_KLhe_02_XIX_Klima_LIN7: start 20, 1 bit, little-endian, data-type-policy=OVERRIDE, i-signal-type=PRIMITIVE, init-value=0, base-type=BT_KBI_Einheit_Uhrzeit, compu {0=Cx0_24h (CM_KBI_Einheit_Uhrzeit_Cx0_24h), 1=Cx1_12h_AM_PM (CM_KBI_Einheit_Uhrzeit_Cx1_12h_AM_PM) (12h AM/PM)}, range raw 0..1, transfer-property=PENDING  # Anzeigevariante der Uhrzeit
            signal HLR_SIH_Freigabe_Fond_XIX_KLhe_02_XIX_Klima_LIN7: start 21, 1 bit, little-endian, data-type-policy=OVERRIDE, i-signal-type=PRIMITIVE, init-value=0, base-type=BT_HLR_SIH_Freigabe_Fond, compu {0=Cx0_keine_Freigabe (CM_HLR_SIH_Freigabe_Fond_Cx0_keine_Freigabe), 1=Cx1_Freigabe (CM_HLR_SIH_Freigabe_Fond_Cx1_Freigabe)}, range raw 0..1, transfer-property=PENDING  # Freigabe des EM für Sitzheizungen hinten
            signal BCM_Remotestart_Betrieb_XIX_KLhe_02_XIX_Klima_LIN7: start 22, 1 bit, little-endian, data-type-policy=OVERRIDE, i-signal-type=PRIMITIVE, init-value=0, base-type=BT_BCM_Remotestart_Betrieb, compu {0=Cx0_kein_RS_Betrieb (CM_BCM_Remotestart_Betrieb_Cx0_kein_RS_Betrieb), 1=Cx1_RS_Betrieb (CM_BCM_Remotestart_Betrieb_Cx1_RS_Betrieb)}, range raw 0..1, transfer-property=PENDING  # Zeigt den Status des RemoteStarts an, d.h. KL15_RSt ist aktiviert und der Motorlauf ist im RSt-Betrieb aktiv.
            signal UH_Minute_XIX_KLhe_02_XIX_Klima_LIN7: start 32, 6 bit, little-endian, data-type-policy=OVERRIDE, i-signal-type=PRIMITIVE, init-value=0, base-type=BT_UH_Minute, compu {phys=raw for raw 0..59; unit Unit_Minut}, range phys 0..59 Unit_Minut, raw 0..59, unit=Unit_Minut, transfer-property=PENDING  # 0x3C- 0x3f = Werte ungültig
            signal UH_Stunde_XIX_KLhe_02_XIX_Klima_LIN7: start 38, 5 bit, little-endian, data-type-policy=OVERRIDE, i-signal-type=PRIMITIVE, init-value=0, base-type=BT_UH_Stunde, compu {phys=raw for raw 0..23; unit Unit_Hours}, range phys 0..23 Unit_Hours, raw 0..23, unit=Unit_Hours, transfer-property=PENDING  # 0x18 - 0x1F = Werte ungültig
            signal SIL_Stufe_LED_HL_XIX_KLhe_02_XIX_Klima_LIN7: start 43, 3 bit, little-endian, data-type-policy=OVERRIDE, i-signal-type=PRIMITIVE, init-value=0, base-type=BT_SIL_Stufe_LED_HL, compu {0=Cx0_Aus (CM_SIL_Stufe_LED_HL_Cx0_Aus), 1=Cx1_Stufe_1 (CM_SIL_Stufe_LED_HL_Cx1_Stufe_1), 2=Cx2_Stufe_2 (CM_SIL_Stufe_LED_HL_Cx2_Stufe_2), 3=Cx3_Stufe_3 (CM_SIL_Stufe_LED_HL_Cx3_Stufe_3), 4=Cx4_Stufe_4 (CM_SIL_Stufe_LED_HL_Cx4_Stufe_4), 5=Cx5_Stufe_5 (CM_SIL_Stufe_LED_HL_Cx5_Stufe_5), 6=Cx6_Stufe_6 (CM_SIL_Stufe_LED_HL_Cx6_Stufe_6)}, range raw 0..6, transfer-property=PENDING  # Statusmeldung Sitzlüftung hinten links
            signal SIL_Stufe_LED_HR_XIX_KLhe_02_XIX_Klima_LIN7: start 46, 3 bit, little-endian, data-type-policy=OVERRIDE, i-signal-type=PRIMITIVE, init-value=0, base-type=BT_SIL_Stufe_LED_HR, compu {0=Cx0_Aus (CM_SIL_Stufe_LED_HR_Cx0_Aus), 1=Cx1_Stufe_1 (CM_SIL_Stufe_LED_HR_Cx1_Stufe_1), 2=Cx2_Stufe_2 (CM_SIL_Stufe_LED_HR_Cx2_Stufe_2), 3=Cx3_Stufe_3 (CM_SIL_Stufe_LED_HR_Cx3_Stufe_3), 4=Cx4_Stufe_4 (CM_SIL_Stufe_LED_HR_Cx4_Stufe_4), 5=Cx5_Stufe_5 (CM_SIL_Stufe_LED_HR_Cx5_Stufe_5), 6=Cx6_Stufe_6 (CM_SIL_Stufe_LED_HR_Cx6_Stufe_6)}, range raw 0..6, transfer-property=PENDING  # Statusmeldung Sitzlüftung hinten rechts
            signal FCM_01_alt_XIX_KLhe_02_XIX_Klima_LIN7: start 63, 1 bit, little-endian, data-type-policy=OVERRIDE, i-signal-type=PRIMITIVE, init-value=1, base-type=BT_FCM_01_alt, compu {0=Cx0_aktuell (CM_FCM_01_alt_Cx0_aktuell), 1=Cx1_veraltet (CM_FCM_01_alt_Cx1_veraltet)}, range raw 0..1, transfer-property=PENDING  # Veraltet Bit für die Botschaft FCM_01
        frame KLhs_01_XIX_Klima_LIN7: id 0x2, to Klima, frame-length=8, lin-checksum=ENHANCED
          pdu KLhs_01_XIX_Klima_LIN7: length=8, unused-bit-pattern=0
            signal KLh_Fehler1_XIX_KLhs_01_XIX_Klima_LIN7: start 0, 1 bit, little-endian, data-type-policy=OVERRIDE, i-signal-type=PRIMITIVE, init-value=0, base-type=BT_KLh_Fehler1, compu {0=Cx0_T5_Heck_normal (CM_KLh_Fehler1_Cx0_T5_Heck_normal) (T5 Heck normal), 1=Cx1_T5_Heck_Fehler (CM_KLh_Fehler1_Cx1_T5_Heck_Fehler) (T5 Heck Fehler)}, range raw 0..1, transfer-property=PENDING, to Klima(timeout 3.5 s)  # Heckbedienteil Fehler1
            signal KLh_Fehler2_XIX_KLhs_01_XIX_Klima_LIN7: start 1, 1 bit, little-endian, data-type-policy=OVERRIDE, i-signal-type=PRIMITIVE, init-value=0, base-type=BT_KLh_Fehler2, compu {0=Cx0_T5_Heck_normal (CM_KLh_Fehler2_Cx0_T5_Heck_normal) (T5 Heck normal), 1=Cx1_T5_Heck_Fehler (CM_KLh_Fehler2_Cx1_T5_Heck_Fehler) (T5 Heck Fehler)}, range raw 0..1, transfer-property=PENDING, to Klima(timeout 3.5 s)  # Heckbedienteil Fehler2
            signal KLh_Fehler3_XIX_KLhs_01_XIX_Klima_LIN7: start 2, 1 bit, little-endian, data-type-policy=OVERRIDE, i-signal-type=PRIMITIVE, init-value=0, base-type=BT_KLh_Fehler3, compu {0=Cx0_T5_Heck_normal (CM_KLh_Fehler3_Cx0_T5_Heck_normal) (T5 Heck normal), 1=Cx1_T5_Heck_Fehler (CM_KLh_Fehler3_Cx1_T5_Heck_Fehler) (T5 Heck Fehler)}, range raw 0..1, transfer-property=PENDING, to Klima(timeout 3.5 s)  # Heckbedienteil Fehler3
            signal KLh_Fehler4_XIX_KLhs_01_XIX_Klima_LIN7: start 3, 1 bit, little-endian, data-type-policy=OVERRIDE, i-signal-type=PRIMITIVE, init-value=0, base-type=BT_KLh_Fehler4, compu {0=Cx0_T5_Heck_normal (CM_KLh_Fehler4_Cx0_T5_Heck_normal) (T5 Heck normal), 1=Cx1_T5_Heck_Fehler (CM_KLh_Fehler4_Cx1_T5_Heck_Fehler) (T5 Heck Fehler)}, range raw 0..1, transfer-property=PENDING, to Klima(timeout 3.5 s)  # Heckbedienteil Fehler4
            signal KLh_Fehler5_XIX_KLhs_01_XIX_Klima_LIN7: start 4, 1 bit, little-endian, data-type-policy=OVERRIDE, i-signal-type=PRIMITIVE, init-value=0, base-type=BT_KLh_Fehler5, compu {0=Cx0_T5_Heck_normal (CM_KLh_Fehler5_Cx0_T5_Heck_normal) (T5 Heck normal), 1=Cx1_T5_Heck_Fehler (CM_KLh_Fehler5_Cx1_T5_Heck_Fehler) (T5 Heck Fehler)}, range raw 0..1, transfer-property=PENDING, to Klima(timeout 3.5 s)  # Heckbedienteil Fehler5
            signal KLh_Fehler6_XIX_KLhs_01_XIX_Klima_LIN7: start 5, 1 bit, little-endian, data-type-policy=OVERRIDE, i-signal-type=PRIMITIVE, init-value=0, base-type=BT_KLh_Fehler6, compu {0=Cx0_T5_Heck_normal (CM_KLh_Fehler6_Cx0_T5_Heck_normal) (T5 Heck normal), 1=Cx1_T5_Heck_Fehler (CM_KLh_Fehler6_Cx1_T5_Heck_Fehler) (T5 Heck Fehler)}, range raw 0..1, transfer-property=PENDING, to Klima(timeout 3.5 s)  # Heckbedienteil Fehler6
            signal KLh_Fehler7_XIX_KLhs_01_XIX_Klima_LIN7: start 6, 1 bit, little-endian, data-type-policy=OVERRIDE, i-signal-type=PRIMITIVE, init-value=0, base-type=BT_KLh_Fehler7, compu {0=Cx0_T5_Heck_normal (CM_KLh_Fehler7_Cx0_T5_Heck_normal) (T5 Heck normal), 1=Cx1_T5_Heck_Fehler (CM_KLh_Fehler7_Cx1_T5_Heck_Fehler) (T5 Heck Fehler)}, range raw 0..1, transfer-property=PENDING, to Klima(timeout 3.5 s)  # Heckbedienteil Fehler7
            signal KLh_Fehler8_XIX_KLhs_01_XIX_Klima_LIN7: start 7, 1 bit, little-endian, data-type-policy=OVERRIDE, i-signal-type=PRIMITIVE, init-value=0, base-type=BT_KLh_Fehler8, compu {0=Cx0_T5_Heck_normal (CM_KLh_Fehler8_Cx0_T5_Heck_normal) (T5 Heck normal), 1=Cx1_T5_Heck_Fehler (CM_KLh_Fehler8_Cx1_T5_Heck_Fehler) (T5 Heck Fehler)}, range raw 0..1, transfer-property=PENDING, to Klima(timeout 3.5 s)  # Heckbedienteil Fehler8
            signal KLhl_GeblaeseSoll_XIX_KLhs_01_XIX_Klima_LIN7: start 8, 4 bit, little-endian, data-type-policy=OVERRIDE, i-signal-type=PRIMITIVE, init-value=0, base-type=BT_KLhl_GeblaeseSoll, compu {0=Cx0_keine_Ticks (CM_KLhl_GeblaeseSoll_Cx0_keine_Ticks) (keine Ticks), 1=Cx1_1_Ticks (CM_KLhl_GeblaeseSoll_Cx1_1_Ticks) (+1 Ticks), 2=Cx2_2_Ticks (CM_KLhl_GeblaeseSoll_Cx2_2_Ticks) (+2 Ticks), 3=Cx3_3_Ticks (CM_KLhl_GeblaeseSoll_Cx3_3_Ticks) (+3 Ticks), 4=Cx4_4_Ticks (CM_KLhl_GeblaeseSoll_Cx4_4_Ticks) (+4 Ticks), 5=Cx5_5_Ticks (CM_KLhl_GeblaeseSoll_Cx5_5_Ticks) (+5 Ticks), 6=Cx6_6_Ticks (CM_KLhl_GeblaeseSoll_Cx6_6_Ticks) (+6 Ticks), 7=Cx7_7_Ticks (CM_KLhl_GeblaeseSoll_Cx7_7_Ticks) (+7 Ticks), 8=Cx8_Fehlerwert (CM_KLhl_GeblaeseSoll_Cx8_Fehlerwert), 9=Cx9_7_Ticks (CM_KLhl_GeblaeseSoll_Cx9_7_Ticks) (-7 Ticks), 10=Cxa_6_Ticks (CM_KLhl_GeblaeseSoll_Cxa_6_Ticks) (-6 Ticks), 11=Cxb_5_Ticks (CM_KLhl_GeblaeseSoll_Cxb_5_Ticks) (-5 Ticks), 12=Cxc_5_Ticks (CM_KLhl_GeblaeseSoll_Cxc_5_Ticks) (-5 Ticks), 13=Cxd_3_Ticks (CM_KLhl_GeblaeseSoll_Cxd_3_Ticks) (-3 Ticks), 14=Cxe_2_Ticks (CM_KLhl_GeblaeseSoll_Cxe_2_Ticks) (-2 Ticks), 15=Cxf_1_Ticks (CM_KLhl_GeblaeseSoll_Cxf_1_Ticks) (-1 Ticks)}, range raw 0..15, transfer-property=PENDING, to Klima(timeout 3.5 s)  # VW428
            signal KLhl_TempSoll_XIX_KLhs_01_XIX_Klima_LIN7: start 12, 4 bit, little-endian, data-type-policy=OVERRIDE, i-signal-type=PRIMITIVE, init-value=0, base-type=BT_KLhl_TempSoll, compu {0=Cx0_keine_Ticks (CM_KLhl_TempSoll_Cx0_keine_Ticks) (keine Ticks), 1=Cx1_1_Ticks (CM_KLhl_TempSoll_Cx1_1_Ticks) (+1 Ticks), 2=Cx2_2_Ticks (CM_KLhl_TempSoll_Cx2_2_Ticks) (+2 Ticks), 3=Cx3_3_Ticks (CM_KLhl_TempSoll_Cx3_3_Ticks) (+3 Ticks), 4=Cx4_4_Ticks (CM_KLhl_TempSoll_Cx4_4_Ticks) (+4 Ticks), 5=Cx5_5_Ticks (CM_KLhl_TempSoll_Cx5_5_Ticks) (+5 Ticks), 6=Cx6_6_Ticks (CM_KLhl_TempSoll_Cx6_6_Ticks) (+6 Ticks), 7=Cx7_7_Ticks (CM_KLhl_TempSoll_Cx7_7_Ticks) (+7 Ticks), 8=Cx8_Fehlerwert (CM_KLhl_TempSoll_Cx8_Fehlerwert), 9=Cx9_7_Ticks (CM_KLhl_TempSoll_Cx9_7_Ticks) (-7 Ticks), 10=Cxa_6_Ticks (CM_KLhl_TempSoll_Cxa_6_Ticks) (-6 Ticks), 11=Cxb_5_Ticks (CM_KLhl_TempSoll_Cxb_5_Ticks) (-5 Ticks), 12=Cxc_5_Ticks (CM_KLhl_TempSoll_Cxc_5_Ticks) (-5 Ticks), 13=Cxd_3_Ticks (CM_KLhl_TempSoll_Cxd_3_Ticks) (-3 Ticks), 14=Cxe_2_Ticks (CM_KLhl_TempSoll_Cxe_2_Ticks) (-2 Ticks), 15=Cxf_1_Ticks (CM_KLhl_TempSoll_Cxf_1_Ticks) (-1 Ticks)}, range raw 0..15, transfer-property=PENDING, to Klima(timeout 3.5 s)  # VW428
            signal KLhl_Luft_oben_XIX_KLhs_01_XIX_Klima_LIN7: start 16, 1 bit, little-endian, data-type-policy=OVERRIDE, i-signal-type=PRIMITIVE, init-value=0, base-type=BT_KLhl_Luft_oben, compu {0=Cx0_nicht_betaetigt (CM_KLhl_Luft_oben_Cx0_nicht_betaetigt), 1=Cx1_betaetigt (CM_KLhl_Luft_oben_Cx1_betaetigt)}, range raw 0..1, transfer-property=PENDING, to Klima(timeout 3.5 s)  # VW428
            signal KLhl_Luft_mitte_XIX_KLhs_01_XIX_Klima_LIN7: start 17, 1 bit, little-endian, data-type-policy=OVERRIDE, i-signal-type=PRIMITIVE, init-value=0, base-type=BT_KLhl_Luft_mitte, compu {0=Cx0_nicht_betaetigt (CM_KLhl_Luft_mitte_Cx0_nicht_betaetigt), 1=Cx1_betaetigt (CM_KLhl_Luft_mitte_Cx1_betaetigt)}, range raw 0..1, transfer-property=PENDING, to Klima(timeout 3.5 s)  # Tastendruck "Luftverteilung Mannanströmer Heck"
            signal KLhl_Luft_unten_XIX_KLhs_01_XIX_Klima_LIN7: start 18, 1 bit, little-endian, data-type-policy=OVERRIDE, i-signal-type=PRIMITIVE, init-value=0, base-type=BT_KLhl_Luft_unten, compu {0=Cx0_nicht_betaetigt (CM_KLhl_Luft_unten_Cx0_nicht_betaetigt), 1=Cx1_betaetigt (CM_KLhl_Luft_unten_Cx1_betaetigt)}, range raw 0..1, transfer-property=PENDING, to Klima(timeout 3.5 s)  # Tastendruck "Luftverteilung Fußraum Heck"
            signal KLhl_Luft_auto_XIX_KLhs_01_XIX_Klima_LIN7: start 19, 1 bit, little-endian, data-type-policy=OVERRIDE, i-signal-type=PRIMITIVE, init-value=0, base-type=BT_KLhl_Luft_auto, compu {0=Cx0_nicht_betaetigt (CM_KLhl_Luft_auto_Cx0_nicht_betaetigt), 1=Cx1_betaetigt (CM_KLhl_Luft_auto_Cx1_betaetigt)}, range raw 0..1, transfer-property=PENDING, to Klima(timeout 3.5 s)  # Tastendruck "Auto Heck"
            signal KLhl_Luft_seite_XIX_KLhs_01_XIX_Klima_LIN7: start 20, 1 bit, little-endian, data-type-policy=OVERRIDE, i-signal-type=PRIMITIVE, init-value=0, base-type=BT_KLhl_Luft_seite, compu {0=Cx0_nicht_betaetigt (CM_KLhl_Luft_seite_Cx0_nicht_betaetigt), 1=Cx1_betaetigt (CM_KLhl_Luft_seite_Cx1_betaetigt)}, range raw 0..1, transfer-property=PENDING, to Klima(timeout 3.5 s)  # Tastendruck "Luftverteilung Seitenscheibe Heck"
            signal KLh_Seite_defog_hl_XIX_KLhs_01_XIX_Klima_LIN7: start 21, 1 bit, little-endian, data-type-policy=OVERRIDE, i-signal-type=PRIMITIVE, init-value=0, base-type=BT_KLh_Seite_defog_hl, compu {0=Cx0_nicht_betaetigt (CM_KLh_Seite_defog_hl_Cx0_nicht_betaetigt), 1=Cx1_betaetigt (CM_KLh_Seite_defog_hl_Cx1_betaetigt)}, range raw 0..1, transfer-property=PENDING, to Klima(timeout 3.5 s)  # Tastendruck "defog Heck"
            signal KLh_aus_XIX_KLhs_01_XIX_Klima_LIN7: start 22, 1 bit, little-endian, data-type-policy=OVERRIDE, i-signal-type=PRIMITIVE, base-type=BT_KLh_aus, compu {0=Cx0_Ein (CM_KLh_aus_Cx0_Ein), 1=Cx1_Aus (CM_KLh_aus_Cx1_Aus)}, range raw 0..1, transfer-property=PENDING, to Klima(timeout 3.5 s)  # Zustand HeckBT ein/aus
            signal KLhl_ResponseError_XIX_KLhs_01_XIX_Klima_LIN7: start 23, 1 bit, little-endian, data-type-policy=OVERRIDE, i-signal-type=PRIMITIVE, init-value=0, base-type=BT_KLhl_ResponseError, invalid-value=Invalid_KLhl_ResponseError_XIX_KLhs_01_XIX_Klima_LIN7:1, compu {0=Cx0_normal (CM_KLhl_ResponseError_Cx0_normal), 1=Cx1_Fehler (CM_KLhl_ResponseError_Cx1_Fehler)}, range raw 0..1, transfer-property=PENDING, to Klima(timeout 3.5 s)  # siehe LIN2.0-Specification (Kap 2.7.3) (Darf nicht über ein Fehlergueltigkeitsbit abgesichtert werden!)
            signal KLh_Ausstattung_KlimaHeck_XIX_KLhs_01_XIX_Klima_LIN7: start 24, 3 bit, little-endian, data-type-policy=OVERRIDE, i-signal-type=PRIMITIVE, base-type=BT_KLh_Ausstattung_KlimaHeck, compu {0=Cx0_Heizung_elektrisch (CM_KLh_Ausstattung_KlimaHeck_Cx0_Heizung_elektrisch), 1=Cx1_Klimamanuell_elektrisch (CM_KLh_Ausstattung_KlimaHeck_Cx1_Klimamanuell_elektrisch), 2=Cx2_Climatic_1_Zone (CM_KLh_Ausstattung_KlimaHeck_Cx2_Climatic_1_Zone), 3=Cx3_Climatronic_1_Zone (CM_KLh_Ausstattung_KlimaHeck_Cx3_Climatronic_1_Zone), 4=Cx4_Climatronic_2_Zonen (CM_KLh_Ausstattung_KlimaHeck_Cx4_Climatronic_2_Zonen), 5=Cx5_reserviert (CM_KLh_Ausstattung_KlimaHeck_Cx5_reserviert), 6=Cx6_reserviert (CM_KLh_Ausstattung_KlimaHeck_Cx6_reserviert), 7=Cx7_reserviert (CM_KLh_Ausstattung_KlimaHeck_Cx7_reserviert)}, range raw 0..7, transfer-property=PENDING, to Klima(timeout 3.5 s)  # Austtattungsart der Klimabedienung Heckbedienteil
            signal KLhr_TempSoll_XIX_KLhs_01_XIX_Klima_LIN7: start 27, 4 bit, little-endian, data-type-policy=OVERRIDE, i-signal-type=PRIMITIVE, init-value=0, base-type=BT_KLhr_TempSoll, compu {0=Cx0_keine_Ticks (CM_KLhr_TempSoll_Cx0_keine_Ticks) (keine Ticks), 1=Cx1_1_Ticks (CM_KLhr_TempSoll_Cx1_1_Ticks) (+1 Ticks), 2=Cx2_2_Ticks (CM_KLhr_TempSoll_Cx2_2_Ticks) (+2 Ticks), 3=Cx3_3_Ticks (CM_KLhr_TempSoll_Cx3_3_Ticks) (+3 Ticks), 4=Cx4_4_Ticks (CM_KLhr_TempSoll_Cx4_4_Ticks) (+4 Ticks), 5=Cx5_5_Ticks (CM_KLhr_TempSoll_Cx5_5_Ticks) (+5 Ticks), 6=Cx6_6_Ticks (CM_KLhr_TempSoll_Cx6_6_Ticks) (+6 Ticks), 7=Cx7_7_Ticks (CM_KLhr_TempSoll_Cx7_7_Ticks) (+7 Ticks), 8=Cx8_Fehlerwert (CM_KLhr_TempSoll_Cx8_Fehlerwert), 9=Cx9_7_Ticks (CM_KLhr_TempSoll_Cx9_7_Ticks) (-7 Ticks), 10=Cxa_6_Ticks (CM_KLhr_TempSoll_Cxa_6_Ticks) (-6 Ticks), 11=Cxb_5_Ticks (CM_KLhr_TempSoll_Cxb_5_Ticks) (-5 Ticks), 12=Cxc_5_Ticks (CM_KLhr_TempSoll_Cxc_5_Ticks) (-5 Ticks), 13=Cxd_3_Ticks (CM_KLhr_TempSoll_Cxd_3_Ticks) (-3 Ticks), 14=Cxe_2_Ticks (CM_KLhr_TempSoll_Cxe_2_Ticks) (-2 Ticks), 15=Cxf_1_Ticks (CM_KLhr_TempSoll_Cxf_1_Ticks) (-1 Ticks)}, range raw 0..15, transfer-property=PENDING, to Klima(timeout 3.5 s)  # Verstellung Temperatur 4. Zone durch Bedienelement Heck
            signal KLh_toggle_LVT_XIX_KLhs_01_XIX_Klima_LIN7: start 32, 2 bit, little-endian, data-type-policy=OVERRIDE, i-signal-type=PRIMITIVE, init-value=0, base-type=BT_KLh_toggle_LVT, compu {0=Cx0_nicht_betaetigt (CM_KLh_toggle_LVT_Cx0_nicht_betaetigt), 1=Cx1_betaetigt (CM_KLh_toggle_LVT_Cx1_betaetigt), 2=Cx2_long_push (CM_KLh_toggle_LVT_Cx2_long_push), 3=Cx3_klemmt (CM_KLh_toggle_LVT_Cx3_klemmt)}, range raw 0..3, transfer-property=PENDING, to Klima(timeout 3.5 s)  # Tastendruck "Toggle"
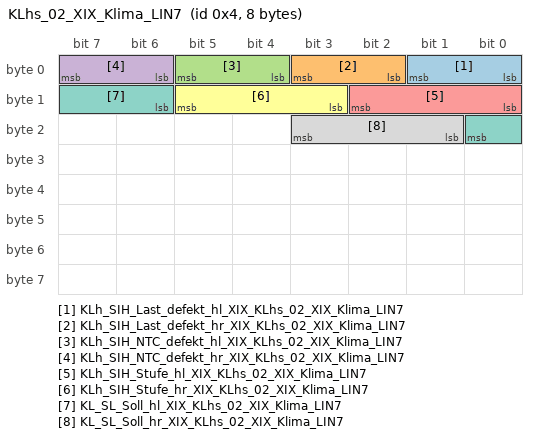
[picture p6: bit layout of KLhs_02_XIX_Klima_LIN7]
        frame KLhs_02_XIX_Klima_LIN7: id 0x4, to Klima, frame-length=8, lin-checksum=ENHANCED
          pdu KLhs_02_XIX_Klima_LIN7: length=8, unused-bit-pattern=0
            signal KLh_SIH_Last_defekt_hl_XIX_KLhs_02_XIX_Klima_LIN7: start 0, 2 bit, little-endian, data-type-policy=OVERRIDE, i-signal-type=PRIMITIVE, base-type=BT_KLh_SIH_Last_defekt_hl, compu {0=Cx0_Kein_Fehler_erkannt (CM_KLh_SIH_Last_defekt_hl_Cx0_Kein_Fehler_erkannt) (Kein Fehler erkannt), 1=Cx1_Unterbrechung (CM_KLh_SIH_Last_defekt_hl_Cx1_Unterbrechung), 2=Cx2_Kurzschluss_nach_Masse (CM_KLh_SIH_Last_defekt_hl_Cx2_Kurzschluss_nach_Masse) (Kurzschluss nach Masse)}, range raw 0..2, transfer-property=PENDING, to Klima(timeout 3.5 s)  # Diagnostizierung Sitzheizung Last Heck links.
            signal KLh_SIH_Last_defekt_hr_XIX_KLhs_02_XIX_Klima_LIN7: start 2, 2 bit, little-endian, data-type-policy=OVERRIDE, i-signal-type=PRIMITIVE, base-type=BT_KLh_SIH_Last_defekt_hr, compu {0=Cx0_Kein_Fehler_erkannt (CM_KLh_SIH_Last_defekt_hr_Cx0_Kein_Fehler_erkannt) (Kein Fehler erkannt), 1=Cx1_Unterbrechung (CM_KLh_SIH_Last_defekt_hr_Cx1_Unterbrechung), 2=Cx2_Kurzschluss_nach_Masse (CM_KLh_SIH_Last_defekt_hr_Cx2_Kurzschluss_nach_Masse) (Kurzschluss nach Masse)}, range raw 0..2, transfer-property=PENDING, to Klima(timeout 3.5 s)  # Diagnostizierung Sitzheizung Last Heck rechts.
            signal KLh_SIH_NTC_defekt_hl_XIX_KLhs_02_XIX_Klima_LIN7: start 4, 2 bit, little-endian, data-type-policy=OVERRIDE, i-signal-type=PRIMITIVE, base-type=BT_KLh_SIH_NTC_defekt_hl, compu {0=Cx0_Kein_Fehler_erkannt (CM_KLh_SIH_NTC_defekt_hl_Cx0_Kein_Fehler_erkannt) (Kein Fehler erkannt), 1=Cx1_Unterbrechung (CM_KLh_SIH_NTC_defekt_hl_Cx1_Unterbrechung), 2=Cx2_Kurzschluss_nach_Masse (CM_KLh_SIH_NTC_defekt_hl_Cx2_Kurzschluss_nach_Masse) (Kurzschluss nach Masse)}, range raw 0..2, transfer-property=PENDING, to Klima(timeout 3.5 s)  # Diagnostizierung Temperaturfühler Sitzheizung Heck links.
            signal KLh_SIH_NTC_defekt_hr_XIX_KLhs_02_XIX_Klima_LIN7: start 6, 2 bit, little-endian, data-type-policy=OVERRIDE, i-signal-type=PRIMITIVE, base-type=BT_KLh_SIH_NTC_defekt_hr, compu {0=Cx0_Kein_Fehler_erkannt (CM_KLh_SIH_NTC_defekt_hr_Cx0_Kein_Fehler_erkannt) (Kein Fehler erkannt), 1=Cx1_Unterbrechung (CM_KLh_SIH_NTC_defekt_hr_Cx1_Unterbrechung), 2=Cx2_Kurzschluss_nach_Masse (CM_KLh_SIH_NTC_defekt_hr_Cx2_Kurzschluss_nach_Masse) (Kurzschluss nach Masse)}, range raw 0..2, transfer-property=PENDING, to Klima(timeout 3.5 s)  # Diagnostizierung Temperaturfühler Sitzheizung Heck rechts.
            signal KLh_SIH_Stufe_hl_XIX_KLhs_02_XIX_Klima_LIN7: start 8, 3 bit, little-endian, data-type-policy=OVERRIDE, i-signal-type=PRIMITIVE, base-type=BT_KLh_SIH_Stufe_hl, compu {0=Cx0_Stufe_0 (CM_KLh_SIH_Stufe_hl_Cx0_Stufe_0), 1=Cx1_Stufe_1 (CM_KLh_SIH_Stufe_hl_Cx1_Stufe_1), 2=Cx2_Stufe_2 (CM_KLh_SIH_Stufe_hl_Cx2_Stufe_2), 3=Cx3_Stufe_3 (CM_KLh_SIH_Stufe_hl_Cx3_Stufe_3), 4=Cx4_Stufe_4 (CM_KLh_SIH_Stufe_hl_Cx4_Stufe_4), 5=Cx5_Stufe_5 (CM_KLh_SIH_Stufe_hl_Cx5_Stufe_5), 6=Cx6_Stufe_6 (CM_KLh_SIH_Stufe_hl_Cx6_Stufe_6)}, range raw 0..6, transfer-property=PENDING, to Klima(timeout 3.5 s)  # Aktive Stufe Sitzheizung Heck links, auf deren Basis die Sitzheizungsmatten bestromt werden. Bei dreistufigen Sitzheizungen wird Stufe 0/2/4/6 verwendet.
            signal KLh_SIH_Stufe_hr_XIX_KLhs_02_XIX_Klima_LIN7: start 11, 3 bit, little-endian, data-type-policy=OVERRIDE, i-signal-type=PRIMITIVE, base-type=BT_KLh_SIH_Stufe_hr, compu {0=Cx0_Stufe_0 (CM_KLh_SIH_Stufe_hr_Cx0_Stufe_0), 1=Cx1_Stufe_1 (CM_KLh_SIH_Stufe_hr_Cx1_Stufe_1), 2=Cx2_Stufe_2 (CM_KLh_SIH_Stufe_hr_Cx2_Stufe_2), 3=Cx3_Stufe_3 (CM_KLh_SIH_Stufe_hr_Cx3_Stufe_3), 4=Cx4_Stufe_4 (CM_KLh_SIH_Stufe_hr_Cx4_Stufe_4), 5=Cx5_Stufe_5 (CM_KLh_SIH_Stufe_hr_Cx5_Stufe_5), 6=Cx6_Stufe_6 (CM_KLh_SIH_Stufe_hr_Cx6_Stufe_6)}, range raw 0..6, transfer-property=PENDING, to Klima(timeout 3.5 s)  # Aktive Stufe Sitzheizung Heck rechts, auf deren Basis die Sitzheizungsmatten bestromt werden. Bei dreistufigen Sitzheizungen wird Stufe 0/2/4/6 verwendet.
            signal KL_SL_Soll_hl_XIX_KLhs_02_XIX_Klima_LIN7: start 14, 3 bit, little-endian, data-type-policy=OVERRIDE, i-signal-type=PRIMITIVE, init-value=0, base-type=BT_KL_SL_Soll_hl, compu {0=Cx0_Stufe_0 (CM_KL_SL_Soll_hl_Cx0_Stufe_0), 1=Cx1_Stufe_1 (CM_KL_SL_Soll_hl_Cx1_Stufe_1), 2=Cx2_Stufe_2 (CM_KL_SL_Soll_hl_Cx2_Stufe_2), 3=Cx3_Stufe_3 (CM_KL_SL_Soll_hl_Cx3_Stufe_3), 4=Cx4_Stufe_4 (CM_KL_SL_Soll_hl_Cx4_Stufe_4), 5=Cx5_Stufe_5 (CM_KL_SL_Soll_hl_Cx5_Stufe_5), 6=Cx6_Stufe_6 (CM_KL_SL_Soll_hl_Cx6_Stufe_6)}, range raw 0..6, transfer-property=PENDING, to Klima(timeout 3.5 s)  # Einstellung Sitzlüftung hinten links (0...6)
            signal KL_SL_Soll_hr_XIX_KLhs_02_XIX_Klima_LIN7: start 17, 3 bit, little-endian, data-type-policy=OVERRIDE, i-signal-type=PRIMITIVE, init-value=0, base-type=BT_KL_SL_Soll_hr, compu {0=Cx0_Stufe_0 (CM_KL_SL_Soll_hr_Cx0_Stufe_0), 1=Cx1_Stufe_1 (CM_KL_SL_Soll_hr_Cx1_Stufe_1), 2=Cx2_Stufe_2 (CM_KL_SL_Soll_hr_Cx2_Stufe_2), 3=Cx3_Stufe_3 (CM_KL_SL_Soll_hr_Cx3_Stufe_3), 4=Cx4_Stufe_4 (CM_KL_SL_Soll_hr_Cx4_Stufe_4), 5=Cx5_Stufe_5 (CM_KL_SL_Soll_hr_Cx5_Stufe_5), 6=Cx6_Stufe_6 (CM_KL_SL_Soll_hr_Cx6_Stufe_6)}, range raw 0..6, transfer-property=PENDING, to Klima(timeout 3.5 s)  # Einstellung Sitzlüftung hinten rechts (0...6)
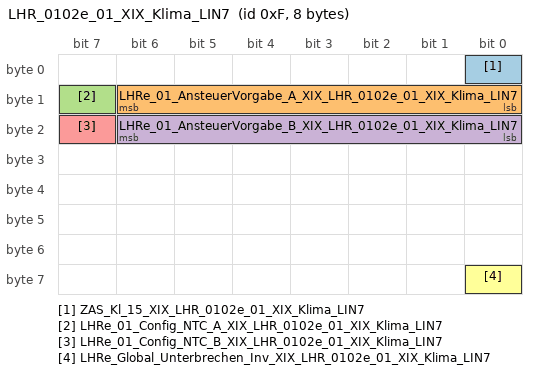
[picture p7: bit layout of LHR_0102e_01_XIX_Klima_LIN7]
        frame LHR_0102e_01_XIX_Klima_LIN7: id 0xF, from Klima, frame-length=8, lin-checksum=ENHANCED
          pdu LHR_0102e_01_XIX_Klima_LIN7: length=8, unused-bit-pattern=0
            signal ZAS_Kl_15_XIX_LHR_0102e_01_XIX_Klima_LIN7: start 0, 1 bit, little-endian, data-type-policy=OVERRIDE, i-signal-type=PRIMITIVE, init-value=0, base-type=BT_ZAS_Kl_15, compu {0=Cx0_aus (CM_ZAS_Kl_15_Cx0_aus), 1=Cx1_ein (CM_ZAS_Kl_15_Cx1_ein)}, range raw 0..1, transfer-property=PENDING  # Klemme 15: Zuendung (SW-Kl.15)
            signal LHRe_01_AnsteuerVorgabe_A_XIX_LHR_0102e_01_XIX_Klima_LIN7: start 8, 7 bit, little-endian, data-type-policy=OVERRIDE, i-signal-type=PRIMITIVE, init-value=0, base-type=BT_LHRe_01_AnsteuerVorgabe_A, invalid-value=Invalid_LHRe_01_AnsteuerVorgabe_A_XIX_LHR_0102e_01_XIX_Klima_LIN7:127, compu {phys=raw for raw 0..100, 101=Cx65_PWM_100Prozent_ohne_U_Kompensat (CM_LHRe_01_AnsteuerVorgabe_A_Cx65_PWM_100Prozent_ohne_U_Kompensat), 110=Cx6e_Stufe_0 (CM_LHRe_01_AnsteuerVorgabe_A_Cx6e_Stufe_0), 111=Cx6f_Stufe_1 (CM_LHRe_01_AnsteuerVorgabe_A_Cx6f_Stufe_1), 112=Cx70_Stufe_2 (CM_LHRe_01_AnsteuerVorgabe_A_Cx70_Stufe_2), 113=Cx71_Stufe_3 (CM_LHRe_01_AnsteuerVorgabe_A_Cx71_Stufe_3), 114=Cx72_Stufe_4 (CM_LHRe_01_AnsteuerVorgabe_A_Cx72_Stufe_4), 115=Cx73_Stufe_5 (CM_LHRe_01_AnsteuerVorgabe_A_Cx73_Stufe_5), 116=Cx74_Stufe_6 (CM_LHRe_01_AnsteuerVorgabe_A_Cx74_Stufe_6), 117=Cx75_Stufe_7 (CM_LHRe_01_AnsteuerVorgabe_A_Cx75_Stufe_7), 118=Cx76_Stufe_8 (CM_LHRe_01_AnsteuerVorgabe_A_Cx76_Stufe_8), 119=Cx77_Stufe_9 (CM_LHRe_01_AnsteuerVorgabe_A_Cx77_Stufe_9), 120=Cx78_Stufe_10 (CM_LHRe_01_AnsteuerVorgabe_A_Cx78_Stufe_10), 127=Cx7f_Fehler (CM_LHRe_01_AnsteuerVorgabe_A_Cx7f_Fehler); unit Unit_PerCent}, range phys 0..100 Unit_PerCent, raw 0..127, unit=Unit_PerCent, transfer-property=PENDING  # Heizvorgabe Kanal A
            signal LHRe_01_Config_NTC_A_XIX_LHR_0102e_01_XIX_Klima_LIN7: start 15, 1 bit, little-endian, data-type-policy=OVERRIDE, i-signal-type=PRIMITIVE, init-value=0, base-type=BT_LHRe_01_Config_NTC_A, compu {0=Cx0_Init_ohne_NTC (CM_LHRe_01_Config_NTC_A_Cx0_Init_ohne_NTC), 1=Cx1_mit_NTC (CM_LHRe_01_Config_NTC_A_Cx1_mit_NTC)}, range raw 0..1, transfer-property=PENDING  # Verbauinformation für NTC a
            signal LHRe_01_AnsteuerVorgabe_B_XIX_LHR_0102e_01_XIX_Klima_LIN7: start 16, 7 bit, little-endian, data-type-policy=OVERRIDE, i-signal-type=PRIMITIVE, init-value=0, base-type=BT_LHRe_01_AnsteuerVorgabe_B, invalid-value=Invalid_LHRe_01_AnsteuerVorgabe_B_XIX_LHR_0102e_01_XIX_Klima_LIN7:127, compu {phys=raw for raw 0..100, 101=Cx65_PWM_100Prozent_ohne_U_Kompensat (CM_LHRe_01_AnsteuerVorgabe_B_Cx65_PWM_100Prozent_ohne_U_Kompensat), 110=Cx6e_Stufe_0 (CM_LHRe_01_AnsteuerVorgabe_B_Cx6e_Stufe_0), 111=Cx6f_Stufe_1 (CM_LHRe_01_AnsteuerVorgabe_B_Cx6f_Stufe_1), 112=Cx70_Stufe_2 (CM_LHRe_01_AnsteuerVorgabe_B_Cx70_Stufe_2), 113=Cx71_Stufe_3 (CM_LHRe_01_AnsteuerVorgabe_B_Cx71_Stufe_3), 114=Cx72_Stufe_4 (CM_LHRe_01_AnsteuerVorgabe_B_Cx72_Stufe_4), 115=Cx73_Stufe_5 (CM_LHRe_01_AnsteuerVorgabe_B_Cx73_Stufe_5), 116=Cx74_Stufe_6 (CM_LHRe_01_AnsteuerVorgabe_B_Cx74_Stufe_6), 117=Cx75_Stufe_7 (CM_LHRe_01_AnsteuerVorgabe_B_Cx75_Stufe_7), 118=Cx76_Stufe_8 (CM_LHRe_01_AnsteuerVorgabe_B_Cx76_Stufe_8), 119=Cx77_Stufe_9 (CM_LHRe_01_AnsteuerVorgabe_B_Cx77_Stufe_9), 120=Cx78_Stufe_10 (CM_LHRe_01_AnsteuerVorgabe_B_Cx78_Stufe_10), 127=Cx7f_Fehler (CM_LHRe_01_AnsteuerVorgabe_B_Cx7f_Fehler); unit Unit_PerCent}, range phys 0..100 Unit_PerCent, raw 0..127, unit=Unit_PerCent, transfer-property=PENDING  # Heizvorgabe Kanal B
            signal LHRe_01_Config_NTC_B_XIX_LHR_0102e_01_XIX_Klima_LIN7: start 23, 1 bit, little-endian, data-type-policy=OVERRIDE, i-signal-type=PRIMITIVE, init-value=0, base-type=BT_LHRe_01_Config_NTC_B, compu {0=Cx0_Init_ohne_NTC (CM_LHRe_01_Config_NTC_B_Cx0_Init_ohne_NTC), 1=Cx1_mit_NTC (CM_LHRe_01_Config_NTC_B_Cx1_mit_NTC)}, range raw 0..1, transfer-property=PENDING  # Verbauinformation für NTC B
            signal LHRe_Global_Unterbrechen_Inv_XIX_LHR_0102e_01_XIX_Klima_LIN7: start 56, 1 bit, little-endian, data-type-policy=OVERRIDE, i-signal-type=PRIMITIVE, init-value=0, base-type=BT_LHRe_Global_Unterbrechen_Inv, compu {0=Cx0_Globale_Unterbrechung (CM_LHRe_Global_Unterbrechen_Inv_Cx0_Globale_Unterbrechung), 1=Cx1_Keine_Unterbrechung_Init (CM_LHRe_Global_Unterbrechen_Inv_Cx1_Keine_Unterbrechung_Init)}, range raw 0..1, transfer-property=PENDING  # Alle LHR-Slaves werden mit diesem Signal über eine temporäre Abschaltung informiert, damit sie so schnell wie möglich abschalten können um die Motor-Wiederstartanforderung zu erfüllen und andere Sofortabschaltungen umzusetzen.
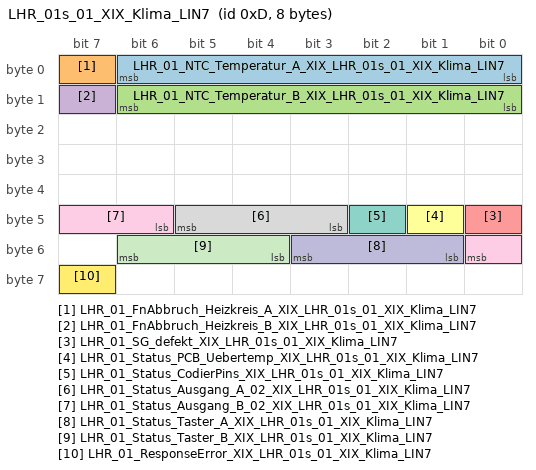
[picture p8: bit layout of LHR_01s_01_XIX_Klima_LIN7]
        frame LHR_01s_01_XIX_Klima_LIN7: id 0xD, to Klima, frame-length=8, lin-checksum=ENHANCED
          pdu LHR_01s_01_XIX_Klima_LIN7: length=8, unused-bit-pattern=0
            signal LHR_01_NTC_Temperatur_A_XIX_LHR_01s_01_XIX_Klima_LIN7: start 0, 7 bit, little-endian, data-type-policy=OVERRIDE, i-signal-type=PRIMITIVE, init-value=125, base-type=BT_LHR_01_NTC_Temperatur_A, compu {phys=raw-40 for raw 0..120, 125=Cx7d_NTC_ungetested_init (CM_LHR_01_NTC_Temperatur_A_Cx7d_NTC_ungetested_init), 126=Cx7e_OpenLoad_Kurzschluss_Plus (CM_LHR_01_NTC_Temperatur_A_Cx7e_OpenLoad_Kurzschluss_Plus), 127=Cx7f_Overload_Kurzschluss_Masse (CM_LHR_01_NTC_Temperatur_A_Cx7f_Overload_Kurzschluss_Masse); unit Unit_DegreCelsi}, range phys -40..80 Unit_DegreCelsi, raw 0..127, unit=Unit_DegreCelsi, transfer-property=PENDING, to Klima(timeout 3.5 s)  # Isttemperatur am NTC A
            signal LHR_01_FnAbbruch_Heizkreis_A_XIX_LHR_01s_01_XIX_Klima_LIN7: start 7, 1 bit, little-endian, data-type-policy=OVERRIDE, i-signal-type=PRIMITIVE, init-value=0, base-type=BT_LHR_01_FnAbbruch_Heizkreis_A, compu {0=Cx0_Init_OK (CM_LHR_01_FnAbbruch_Heizkreis_A_Cx0_Init_OK), 1=Cx1_Funktionsabbruch (CM_LHR_01_FnAbbruch_Heizkreis_A_Cx1_Funktionsabbruch)}, range raw 0..1, transfer-property=PENDING, to Klima(timeout 3.5 s)  # Heizungsregler hat Heizvorgang aufgrund von Fehler abgebrochen (wartet auf Neuinitialisierung)
            signal LHR_01_NTC_Temperatur_B_XIX_LHR_01s_01_XIX_Klima_LIN7: start 8, 7 bit, little-endian, data-type-policy=OVERRIDE, i-signal-type=PRIMITIVE, init-value=125, base-type=BT_LHR_01_NTC_Temperatur_B, compu {phys=raw-40 for raw 0..120, 125=Cx7d_NTC_ungetested_init (CM_LHR_01_NTC_Temperatur_B_Cx7d_NTC_ungetested_init), 126=Cx7e_OpenLoad_Kurzschluss_Plus (CM_LHR_01_NTC_Temperatur_B_Cx7e_OpenLoad_Kurzschluss_Plus), 127=Cx7f_Overload_Kurzschluss_Masse (CM_LHR_01_NTC_Temperatur_B_Cx7f_Overload_Kurzschluss_Masse); unit Unit_DegreCelsi}, range phys -40..80 Unit_DegreCelsi, raw 0..127, unit=Unit_DegreCelsi, transfer-property=PENDING, to Klima(timeout 3.5 s)  # Isttemperatur am NTC B
            signal LHR_01_FnAbbruch_Heizkreis_B_XIX_LHR_01s_01_XIX_Klima_LIN7: start 15, 1 bit, little-endian, data-type-policy=OVERRIDE, i-signal-type=PRIMITIVE, init-value=0, base-type=BT_LHR_01_FnAbbruch_Heizkreis_B, compu {0=Cx0_Init_OK (CM_LHR_01_FnAbbruch_Heizkreis_B_Cx0_Init_OK), 1=Cx1_Funktionsabbruch (CM_LHR_01_FnAbbruch_Heizkreis_B_Cx1_Funktionsabbruch)}, range raw 0..1, transfer-property=PENDING, to Klima(timeout 3.5 s)  # Heizungsregler hat Heizvorgang aufgrund von Fehler abgebrochen (wartet auf Neuinitialisierung)
            signal LHR_01_SG_defekt_XIX_LHR_01s_01_XIX_Klima_LIN7: start 40, 1 bit, little-endian, data-type-policy=OVERRIDE, i-signal-type=PRIMITIVE, init-value=0, base-type=BT_LHR_01_SG_defekt, compu {0=Cx0_Init_OK (CM_LHR_01_SG_defekt_Cx0_Init_OK), 1=Cx1_SG_defekt (CM_LHR_01_SG_defekt_Cx1_SG_defekt)}, range raw 0..1, transfer-property=PENDING, to Klima(timeout 3.5 s)  # Heizungsregler hat irreversiblen defekt
            signal LHR_01_Status_PCB_Uebertemp_XIX_LHR_01s_01_XIX_Klima_LIN7: start 41, 1 bit, little-endian, data-type-policy=OVERRIDE, i-signal-type=PRIMITIVE, init-value=0, base-type=BT_LHR_01_Status_PCB_Uebertemp, compu {0=Cx0_Init_OK (CM_LHR_01_Status_PCB_Uebertemp_Cx0_Init_OK), 1=Cx1_Uebertemperatur (CM_LHR_01_Status_PCB_Uebertemp_Cx1_Uebertemperatur)}, range raw 0..1, transfer-property=PENDING, to Klima(timeout 3.5 s)  # Status der Leiterplattentemperatur
            signal LHR_01_Status_CodierPins_XIX_LHR_01s_01_XIX_Klima_LIN7: start 42, 1 bit, little-endian, data-type-policy=OVERRIDE, i-signal-type=PRIMITIVE, init-value=0, base-type=BT_LHR_01_Status_CodierPins, compu {0=Cx0_Init_OK (CM_LHR_01_Status_CodierPins_Cx0_Init_OK), 1=Cx1_HW_Codierung_Fehler (CM_LHR_01_Status_CodierPins_Cx1_HW_Codierung_Fehler)}, range raw 0..1, transfer-property=PENDING, to Klima(timeout 3.5 s)  # Status der Codierung (Abgleich HW und Softwarecodierung)
            signal LHR_01_Status_Ausgang_A_02_XIX_LHR_01s_01_XIX_Klima_LIN7: start 43, 3 bit, little-endian, data-type-policy=OVERRIDE, i-signal-type=PRIMITIVE, init-value=0, base-type=BT_LHR_01_Status_Ausgang_A_02, compu {0=Cx0_ungetestet (CM_LHR_01_Status_Ausgang_A_02_Cx0_ungetestet), 1=Cx1_Sitzheizung_erkannt (CM_LHR_01_Status_Ausgang_A_02_Cx1_Sitzheizung_erkannt), 2=Cx2_Sitzheizung_nicht_erkannt (CM_LHR_01_Status_Ausgang_A_02_Cx2_Sitzheizung_nicht_erkannt), 3=Cx3_Overload (CM_LHR_01_Status_Ausgang_A_02_Cx3_Overload), 4=Cx4_Openload (CM_LHR_01_Status_Ausgang_A_02_Cx4_Openload)}, range raw 0..4, transfer-property=PENDING, to Klima(timeout 3.5 s)  # Status des Leistungstreibers A. Verbau der Sitzheizung und Kurzschlussprüfung nach Masse oder nach Plus.
            signal LHR_01_Status_Ausgang_B_02_XIX_LHR_01s_01_XIX_Klima_LIN7: start 46, 3 bit, little-endian, data-type-policy=OVERRIDE, i-signal-type=PRIMITIVE, init-value=0, base-type=BT_LHR_01_Status_Ausgang_B_02, compu {0=Cx0_ungetestet (CM_LHR_01_Status_Ausgang_B_02_Cx0_ungetestet), 1=Cx1_Sitzheizung_erkannt (CM_LHR_01_Status_Ausgang_B_02_Cx1_Sitzheizung_erkannt), 2=Cx2_Sitzheizung_nicht_erkannt (CM_LHR_01_Status_Ausgang_B_02_Cx2_Sitzheizung_nicht_erkannt), 3=Cx3_Overload (CM_LHR_01_Status_Ausgang_B_02_Cx3_Overload), 4=Cx4_Openload (CM_LHR_01_Status_Ausgang_B_02_Cx4_Openload)}, range raw 0..4, transfer-property=PENDING, to Klima(timeout 3.5 s)  # Status des Leistungstreibers A. Verbau der Sitzheizung und Kurzschlussprüfung nach Masse oder nach Plus.
            signal LHR_01_Status_Taster_A_XIX_LHR_01s_01_XIX_Klima_LIN7: start 49, 3 bit, little-endian, data-type-policy=OVERRIDE, i-signal-type=PRIMITIVE, init-value=0, base-type=BT_LHR_01_Status_Taster_A, compu {0=Cx0_ungetestet (CM_LHR_01_Status_Taster_A_Cx0_ungetestet), 1=Cx1_Taster_nicht_erkannt (CM_LHR_01_Status_Taster_A_Cx1_Taster_nicht_erkannt), 2=Cx2_Taster_Stufe_0 (CM_LHR_01_Status_Taster_A_Cx2_Taster_Stufe_0), 3=Cx3_Taster_Stufe_1 (CM_LHR_01_Status_Taster_A_Cx3_Taster_Stufe_1), 4=Cx4_Taster_Stufe_2 (CM_LHR_01_Status_Taster_A_Cx4_Taster_Stufe_2), 5=Cx5_Taster_Stufe_3 (CM_LHR_01_Status_Taster_A_Cx5_Taster_Stufe_3)}, range raw 0..5, transfer-property=PENDING, to Klima(timeout 3.5 s)  # Status des Sitzheizungstasters, Kanal A
            signal LHR_01_Status_Taster_B_XIX_LHR_01s_01_XIX_Klima_LIN7: start 52, 3 bit, little-endian, data-type-policy=OVERRIDE, i-signal-type=PRIMITIVE, init-value=0, base-type=BT_LHR_01_Status_Taster_B, compu {0=Cx0_ungetestet (CM_LHR_01_Status_Taster_B_Cx0_ungetestet), 1=Cx1_Taster_nicht_erkannt (CM_LHR_01_Status_Taster_B_Cx1_Taster_nicht_erkannt), 2=Cx2_Taster_Stufe_0 (CM_LHR_01_Status_Taster_B_Cx2_Taster_Stufe_0), 3=Cx3_Taster_Stufe_1 (CM_LHR_01_Status_Taster_B_Cx3_Taster_Stufe_1), 4=Cx4_Taster_Stufe_2 (CM_LHR_01_Status_Taster_B_Cx4_Taster_Stufe_2), 5=Cx5_Taster_Stufe_3 (CM_LHR_01_Status_Taster_B_Cx5_Taster_Stufe_3)}, range raw 0..5, transfer-property=PENDING, to Klima(timeout 3.5 s)  # Status des Sitzheizungstasters, Kanal B
            signal LHR_01_ResponseError_XIX_LHR_01s_01_XIX_Klima_LIN7: start 63, 1 bit, little-endian, data-type-policy=OVERRIDE, i-signal-type=PRIMITIVE, init-value=0, base-type=BT_LHR_01_ResponseError, invalid-value=Invalid_LHR_01_ResponseError_XIX_LHR_01s_01_XIX_Klima_LIN7:1, compu {0=Cx0_normal (CM_LHR_01_ResponseError_Cx0_normal), 1=Cx1_Fehler (CM_LHR_01_ResponseError_Cx1_Fehler)}, range raw 0..1, transfer-property=PENDING, to Klima(timeout 3.5 s)  # siehe LIN2.0-Specification (Darf nicht über ein Fehlergueltigkeitsbit abgesichtert werden!)
        frame MasterReq_XIX_Klima_LIN7: id 0x3C, from Klima, frame-length=8, lin-checksum=CLASSIC
          n pdu MasterReq_XIX_Klima_LIN7: length=8
        frame SlaveResp_XIX_Klima_LIN7: id 0x3D, to Klima, frame-length=8, lin-checksum=CLASSIC
          n pdu SlaveResp_XIX_Klima_LIN7: length=8
        pdu triggering PT_Klima_LIN7_XIX_TPCHType_LIN_Diagnose_XIX_0x0_XIX_0x2_XIX_Physical: pdu=DCM_Klima_LIN7_XIX_TPCHType_LIN_Diagnose_XIX_0x0_XIX_0x2_XIX_Physical, from Klima
        pdu triggering PT_Klima_LIN7_XIX_TPCHType_LIN_Diagnose_XIX_0x0_XIX_0x37_XIX_Physical: pdu=DCM_Klima_LIN7_XIX_TPCHType_LIN_Diagnose_XIX_0x0_XIX_0x37_XIX_Physical, from Klima
        pdu triggering PT_Klima_LIN7_XIX_TPCHType_LIN_Diagnose_XIX_0x0_XIX_0x4E_XIX_Physical: pdu=DCM_Klima_LIN7_XIX_TPCHType_LIN_Diagnose_XIX_0x0_XIX_0x4E_XIX_Physical, from Klima
        pdu triggering PT_Klima_LIN7_XIX_TPCHType_LIN_Diagnose_XIX_0x0_XIX_0x50_XIX_Physical: pdu=DCM_Klima_LIN7_XIX_TPCHType_LIN_Diagnose_XIX_0x0_XIX_0x50_XIX_Physical, from Klima
        pdu triggering PT_Klima_LIN7_XIX_TPCHType_LIN_Diagnose_XIX_0x0_XIX_0x63_XIX_Physical: pdu=DCM_Klima_LIN7_XIX_TPCHType_LIN_Diagnose_XIX_0x0_XIX_0x63_XIX_Physical, from Klima
        pdu triggering PT_Klima_LIN7_XIX_TPCHType_LIN_Diagnose_XIX_0x2_XIX_0x0_XIX_Physical: pdu=DCM_Klima_LIN7_XIX_TPCHType_LIN_Diagnose_XIX_0x2_XIX_0x0_XIX_Physical, to Klima
        pdu triggering PT_Klima_LIN7_XIX_TPCHType_LIN_Diagnose_XIX_0x37_XIX_0x0_XIX_Physical: pdu=DCM_Klima_LIN7_XIX_TPCHType_LIN_Diagnose_XIX_0x37_XIX_0x0_XIX_Physical, to Klima
        pdu triggering PT_Klima_LIN7_XIX_TPCHType_LIN_Diagnose_XIX_0x4E_XIX_0x0_XIX_Physical: pdu=DCM_Klima_LIN7_XIX_TPCHType_LIN_Diagnose_XIX_0x4E_XIX_0x0_XIX_Physical, to Klima
        pdu triggering PT_Klima_LIN7_XIX_TPCHType_LIN_Diagnose_XIX_0x50_XIX_0x0_XIX_Physical: pdu=DCM_Klima_LIN7_XIX_TPCHType_LIN_Diagnose_XIX_0x50_XIX_0x0_XIX_Physical, to Klima
        pdu triggering PT_Klima_LIN7_XIX_TPCHType_LIN_Diagnose_XIX_0x63_XIX_0x0_XIX_Physical: pdu=DCM_Klima_LIN7_XIX_TPCHType_LIN_Diagnose_XIX_0x63_XIX_0x0_XIX_Physical, to Klima
        4 x lin schedule table, all with resume-position=CONTINUE-AT-IT-POSITION:
          DiagRequest: run-mode=RUN-ONCE, application-entry{delay=0.01, position-in-table=0, frame-triggering=CHNL/FT_MasterReq}
          DiagResponse: run-mode=RUN-ONCE, application-entry{delay=0.01, position-in-table=0, frame-triggering=CHNL/FT_SlaveResp}
          st_main_1: run-mode=RUN-CONTINUOUS
            table-entrys:
              delay=0.09, position-in-table=0, frame-triggering=FT_BLOWER1b_SET
              delay=0.01, position-in-table=1, frame-triggering=CHNL/FT_LHR_0102e_01
              delay=0.09, position-in-table=2, frame-triggering=FT_BLOWER1b_STATUS
              delay=0.01, position-in-table=3, frame-triggering=CHNL/FT_LHR_01s_01
          st_main_2: run-mode=RUN-CONTINUOUS
            table-entrys:
              delay=0.01, position-in-table=0, frame-triggering=FT_BLOWER1b_SET
              delay=0.01, position-in-table=1, frame-triggering=CHNL/FT_KLhe_01
              delay=0.01, position-in-table=2, frame-triggering=CHNL/FT_KLhe_02
              delay=0.01, position-in-table=3, frame-triggering=FT_HV_H3be_01
              delay=0.01, position-in-table=4, frame-triggering=FT_DTS2cs_R744_01
              delay=0.01, position-in-table=5, frame-triggering=CHNL/FT_KLhs_01
              delay=0.01, position-in-table=6, frame-triggering=CHNL/FT_KLhs_02
              delay=0.01, position-in-table=7, frame-triggering=CHNL/FT_EVe_01_Control
              delay=0.01, position-in-table=8, frame-triggering=FT_HV_H3bs_01
              delay=0.01, position-in-table=9, frame-triggering=CHNL/FT_LHR_0102e_01
              delay=0.01, position-in-table=10, frame-triggering=FT_BLOWER1b_STATUS
              delay=0.01, position-in-table=11, frame-triggering=CHNL/FT_KLhe_01
              delay=0.01, position-in-table=12, frame-triggering=CHNL/FT_KLhe_02
              delay=0.01, position-in-table=13, frame-triggering=FT_HV_H3be_01
              delay=0.01, position-in-table=14, frame-triggering=FT_DTS2cs_R744_01
              delay=0.01, position-in-table=15, frame-triggering=CHNL/FT_KLhs_01
              delay=0.01, position-in-table=16, frame-triggering=CHNL/FT_KLhs_02
              delay=0.01, position-in-table=17, frame-triggering=FT_EXV4s_01
              delay=0.01, position-in-table=18, frame-triggering=FT_HV_H3bs_01
              delay=0.01, position-in-table=19, frame-triggering=CHNL/FT_LHR_01s_01
